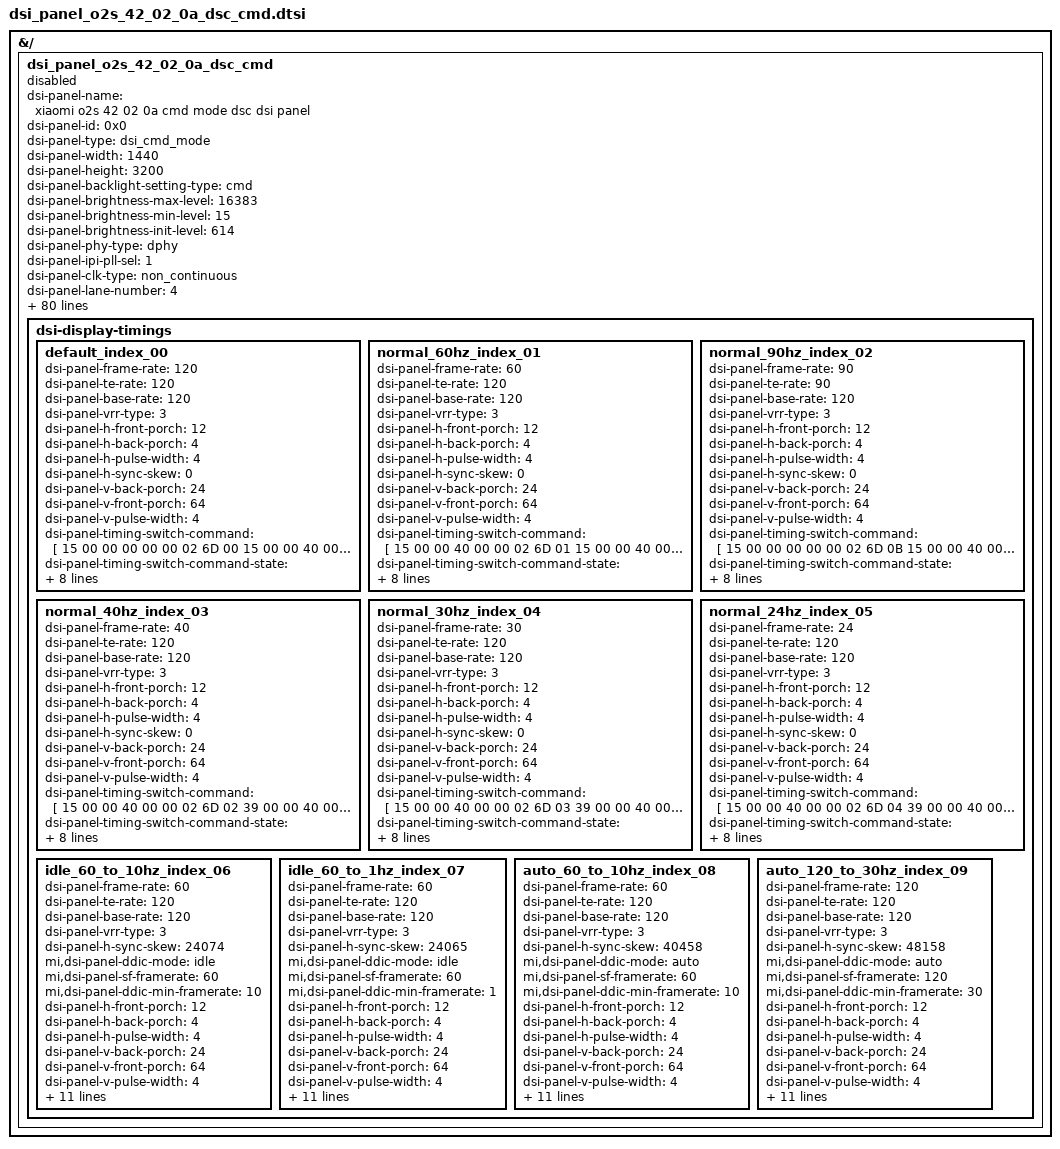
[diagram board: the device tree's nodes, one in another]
// SPDX-License-Identifier: GPL-2.0+
/*
 * DSI panel device tree for o2s testing
 *
 * (C) Copyright 2023 - 2024, X-Ring, Inc.
 */
&{/} {
	dsi_panel_o2s_42_02_0a_dsc_cmd: dsi_panel_o2s_42_02_0a_dsc_cmd {
		status = "disabled";
		dsi-panel-name = "xiaomi o2s 42 02 0a cmd mode dsc dsi panel";
		dsi-panel-id = <0x0>;
		dsi-panel-type = "dsi_cmd_mode";
		dsi-panel-width = <1440>;
		dsi-panel-height = <3200>;
		dsi-panel-backlight-setting-type = "cmd";
		dsi-panel-brightness-max-level = <16383>;
		dsi-panel-brightness-min-level = <15>;
		dsi-panel-brightness-init-level = <614>;
		dsi-panel-phy-type = "dphy";
		dsi-panel-ipi-pll-sel = <1>; // 0:phy pll 1:dpu pll
		dsi-panel-clk-type = "non_continuous";
		dsi-panel-lane-number = <4>;
		dsi-panel-lane-rate = <1360000000>; // 1.36GHz
		dsi-panel-pixel-clock = <26154000>; //26.154MHz
		dsi-panel-bpp = <30>;
		dsi-panel-virtual-channel = <0>;
		dsi-panel-bta-enable;
		dsi-panel-eotp-enable;
		dsi-panel-hdr-enabled;
		dsi-panel-peak-brightness = <12500000>;
		dsi-panel-blackness-level = <3230>;
		dsi-panel-physical-width-dimension = <701>;
		dsi-panel-physical-height-dimension = <1558>;
		dsi-panel-physical-type = "ltpo";
		dsi-panel-te-sel = /bits/ 8 <0x0>;
		dsi-panel-port-mask = /bits/ 8 <0x1>; // DSI-0: 0001
		dsi-panel-boot-up-profile = <1>; //profile-1
		dsi-panel-lowpower-ctrl = <0x3fd>;
		dsi-panel-frame-power-mask = <0x6>;
		dsi-panel-frame-power-max-refresh-rate = <30>;
		dsi-panel-hw-ulps-max-refresh-rate = <30>;
		dsi-panel-idle-policy = <0x0>;
		dsi-panel-dsc-compression-mode = "dsc";
		dsi-panel-dsc-version = <0x12>;
		dsi-panel-dsc-scr-version = <0>;
		dsi-panel-dsc-pic-height = <3200>;
		dsi-panel-dsc-pic-width = <1440>;
		dsi-panel-dsc-slice-height = <20>;
		dsi-panel-dsc-slice-width = <720>;
		dsi-panel-dsc-bpc = /bits/ 8 <10>;
		dsi-panel-dsc-bpp = /bits/ 8 <8>;
		dsi-panel-dsc-pps-table = [
			12 00 00 AB 30 80 0C 80 05 A0 00 14 02 D0 02 D0
			02 00 02 68 00 20 02 2E 00 0A 00 0C 05 0E 03 D1
			18 00 10 F0 07 10 20 00 06 0F 0F 33 0E 1C 2A 38
			46 54 62 69 70 77 79 7B 7D 7E 02 02 22 00 2A 40
			2A BE 3A FC 3A FA 3A F8 3B 38 3B 78 3B B6 4B B6
			4B F4 4B F4 6C 34 84 74 00 00 00 00 00 00 00 00
			00 00 00 00 00 00 00 00 00 00 00 00 00 00 00 00
			00 00 00 00 00 00 00 00 00 00 00 00 00 00 00 00
		];
		dsi-panel-vrr-enable;
		dsi-panel-reset-after-lp11;
		dsi-display-timings {
			default_index_00 {
				#include "dsi_panel_o2s_42_02_0a_dsc_cmd_common.dtsi"
				dsi-panel-frame-rate = <120>;
				dsi-panel-te-rate = <120>;
				dsi-panel-base-rate = <120>;
				dsi-panel-vrr-type = <3>;
				dsi-panel-h-front-porch = <12>;
				dsi-panel-h-back-porch = <4>;
				dsi-panel-h-pulse-width = <4>;
				dsi-panel-h-sync-skew = <0>;
				dsi-panel-v-back-porch = <24>;
				dsi-panel-v-front-porch = <64>;
				dsi-panel-v-pulse-width = <4>;
				dsi-panel-timing-switch-command = [
					//120hz
					15 00 00 00 00 00 02 6D 00
					//fix TE
					15 00 00 40 00 00 02 6F 14
					15 00 00 40 00 00 02 35 00
					15 00 00 40 00 00 02 6F 04
					15 00 00 00 00 00 02 35 00
				];
				dsi-panel-timing-switch-command-state = "dsi_hs_mode";
				dsi-panel-on-command = [
					#include "dsi_panel_o2s_42_02_0a_dsc_cmd_on_common.dtsi"
					//timing config
					15 00 00 40 00 00 02 2F 32
 					//120HZ
 					15 00 00 00 00 00 02 6D 00
 					//fix TE
 					15 00 00 40 00 00 02 6F 14
					15 00 00 40 00 00 02 35 00
					15 00 00 40 00 00 02 6F 04
					15 00 00 40 00 00 02 35 00
					15 00 00 00 00 00 02 5A 00
					//51 return in fps
					39 00 00 00 00 00 04 8C 00 00 11
					/* Sleep Out */
					05 00 00 00 78 00 01 11
					39 00 00 40 00 00 06 F0 55 AA 52 08 02
					15 00 00 00 00 00 02 CC 10
					39 00 00 40 00 00 06 F0 55 AA 52 08 09
					15 00 00 40 00 00 02 6F 03
					39 00 00 40 00 00 05 B2 20 24 28 2C
					15 00 00 40 00 00 02 B2 02
					15 00 00 40 00 00 02 DD 01
					15 00 00 40 00 00 02 6F 11
					39 00 00 40 00 00 20 B2 00 40 00 00 00 00 00 00 00 00 00 00 00 F0 FA
										FB FD 03 04 05 05 0D 0A 0A 02 02 02 02 00 00 00
					15 00 00 40 00 00 02 6F 11
					39 00 00 40 00 00 20 B2 01 40 00 00 00 00 00 00 00 00 00 0A 0A 07 06
										08 07 07 07 07 07 07 09 08 0A 05 06 05 00 00 00
					15 00 00 40 00 00 02 6F 11
					39 00 00 40 00 00 20 B2 00 41 00 00 00 00 00 00 00 F4 F4 F4 F4 FA FC
										00 02 0A 0C 0C 0A 0A 0A 0A 00 00 00 00 00 00 00
					15 00 00 40 00 00 02 6F 11
					39 00 00 40 00 00 20 B2 01 41 00 00 00 00 00 00 0D 0D 0D 0D 0F 0D 07
										08 07 07 07 07 06 05 05 05 05 04 03 00 00 00 00
					15 00 00 40 00 00 02 6F 11
					39 00 00 40 00 00 20 B2 00 42 00 00 00 00 00 01 01 01 DF FF FF 01 04
										08 0A 0A 12 0C 0A 0A 0A 0A 05 04 03 01 00 00 00
					15 00 00 40 00 00 02 6F 11
					39 00 00 40 00 00 20 B2 01 42 00 00 00 00 00 00 03 03 0A 0A 0A 0A 0B
										0B 0A 09 09 05 05 05 05 03 03 03 00 00 00 00 00
					15 00 00 40 00 00 02 6F 11
					39 00 00 40 00 00 20 B2 00 43 00 00 00 00 00 01 01 CA D7 03 FD 01 05
										0B 0E 06 06 09 0A 0A 08 04 00 00 00 00 00 00 00
					15 00 00 40 00 00 02 6F 11
					39 00 00 40 00 00 20 B2 01 43 00 00 00 00 00 00 03 F8 08 08 08 08 08
										08 0A 0A 04 04 05 05 05 FE 00 00 00 00 00 00 00
					15 00 00 40 00 00 02 6F 11
					39 00 00 40 00 00 20 B2 00 50 00 00 00 00 00 00 00 00 00 00 F3 F3 F3
										F7 F8 00 03 04 0C 0C 0A 0A 0A 06 06 06 00 00 00
					15 00 00 40 00 00 02 6F 11
					39 00 00 40 00 00 20 B2 01 50 00 00 00 00 00 00 00 00 00 0D 0D 0D 0D
										0A 0A 08 08 08 08 08 0A 0F 10 0F 07 08 00 00 00
					15 00 00 40 00 00 02 6F 11
					39 00 00 40 00 00 20 B2 00 51 00 00 00 00 00 00 00 00 00 00 E8 F0 F5
										FA 00 06 09 0A 09 05 09 02 02 00 00 00 00 00 00
					15 00 00 40 00 00 02 6F 11
					39 00 00 40 00 00 20 B2 01 51 00 00 00 00 00 00 00 00 00 00 0F 0F 09
										0B 0A 0A 07 08 08 08 06 04 02 02 02 01 00 00 00
					15 00 00 40 00 00 02 6F 11
					39 00 00 40 00 00 20 B2 00 52 00 00 00 00 00 00 00 00 00 F0 F0 F2 F8
										00 02 02 04 02 06 04 08 02 00 00 00 00 00 00 00
					15 00 00 40 00 00 02 6F 11
					39 00 00 40 00 00 20 B2 01 52 00 00 00 00 00 00 05 0B 0B 0A 0C 09 06
										06 09 0A 09 08 04 06 04 00 00 00 00 00 00 00 00
					15 00 00 40 00 00 02 6F 11
					39 00 00 40 00 00 20 B2 00 53 00 00 00 00 00 00 00 00 00 00 F0 F9 00
										02 02 01 02 02 06 04 08 02 00 00 00 00 00 00 00
					15 00 00 40 00 00 02 6F 11
					39 00 00 40 00 00 20 B2 01 53 00 00 00 00 00 00 05 0B 0B 0A 0C 07 0B
										0A 09 0A 09 08 04 06 04 00 00 00 00 00 00 00 00
					15 00 00 40 00 00 02 6F 11
					39 00 00 40 00 00 20 B2 00 60 00 00 00 00 00 00 00 00 00 00 DD 00 00
										00 00 00 00 00 00 03 08 04 08 06 06 06 00 00 00
					15 00 00 40 00 00 02 6F 11
					39 00 00 40 00 00 20 B2 01 60 00 00 00 00 00 00 00 00 00 00 11 0D 0D
										0A 0A 08 08 08 08 08 09 0A 12 0F 07 08 00 00 00
					15 00 00 40 00 00 02 6F 11
					39 00 00 40 00 00 20 B2 00 61 00 00 00 00 00 00 00 00 BD DD 00 E0 E6
										EC F5 FD 00 06 06 03 08 08 08 06 06 06 00 00 00
					15 00 00 40 00 00 02 6F 11
					39 00 00 40 00 00 20 B2 01 61 00 00 00 00 00 00 00 00 00 00 11 0D 0D
										0A 0A 08 08 08 08 08 0A 0F 10 0F 07 08 00 00 00
					15 00 00 40 00 00 02 6F 11
					39 00 00 40 00 00 20 B2 00 62 00 00 00 00 00 00 00 00 D7 F5 00 DC EC
										F4 03 06 08 08 06 16 0D 0A 0A 06 08 0A 00 00 00
					15 00 00 40 00 00 02 6F 11
					39 00 00 40 00 00 20 B2 01 62 00 00 00 00 00 00 00 00 0C 0C 0E 0D 0A
										09 0A 08 06 06 06 0F 0A 08 03 00 00 00 00 00 00
					15 00 00 40 00 00 02 6F 11
					39 00 00 40 00 00 20 B2 00 63 00 00 00 00 00 00 00 00 00 C7 EF EF FA
										00 0A 0A 0D 14 14 11 0F 0A 0A 06 08 0A 00 00 00
					15 00 00 40 00 00 02 6F 11
					39 00 00 40 00 00 20 B2 01 63 00 00 00 00 00 00 00 00 00 0D 10 0D 0A
										07 08 07 07 06 0A 07 06 05 00 00 00 00 00 00 00
					15 00 00 40 00 00 02 DD 00
					39 00 00 40 00 00 06 F0 55 AA 52 08 02
					15 00 00 00 00 00 02 CC 00
					//vgl lvd 9V
					39 00 00 40 00 00 06 F0 55 AA 52 08 01
					15 00 00 40 00 00 02 6F 03
					39 00 00 00 00 00 03 C7 E7 50
					//force cmd mode
					39 00 00 40 00 00 04 17 30 00 12
					39 00 00 40 00 00 05 FF AA 55 A5 81
					15 00 00 40 00 00 02 6F 0F
					39 00 00 00 00 00 02 FD 80
					//APL Dimming
					39 00 00 40 00 00 06 F0 55 AA 52 08 00
					15 00 00 40 00 00 02 6F 78
					39 00 00 40 00 00 18 B0 11 00 2A 00 C2 01 DA 03 7C 05 B1 08 80 0B EE 0F FF 05 55 05 56 05 55
					15 00 00 40 00 00 02 6F 6F
					39 00 00 40 00 00 07 B0 02 D0 05 A0 02 D0
					39 00 00 40 00 00 06 F0 55 AA 52 08 08
					//Lv0 1260nits
					39 00 00 40 00 00 17 C1 9D FF DD FF FF DD FF FF DD FF FF DD FF FF ED FF FF FF 7F FF 0D FF
					15 00 00 40 00 00 02 6F 1D
					39 00 00 40 00 00 07 C1 00 FF FF 4F 00 FF
					15 00 00 40 00 00 02 6F 23
					39 00 00 40 00 00 15 C1 0D FF DD FF FF DD FF FF DD FF FF DD FF FF ED FF FF BD 2D 00
					//Lv1 1800nits
					15 00 00 40 00 00 02 6F 37
					39 00 00 40 00 00 15 C1 0D FF DD FF FF DD FF FF DD FF FF DD FF FF ED FF FF FF 7F FF
					15 00 00 40 00 00 02 6F 4B
					39 00 00 40 00 00 15 C1 0D FF DD FF FF DD FF FF DD FF FF DD FF FF ED FF FF DF 7F 11
					39 00 00 40 00 00 2D BA 00 0F 00 1D 00 1D 00 31 00 31 00 53 00 53 01 9B 01 9B 01 9C
								01 9C 05 56 05 56 0F FF 0F FF 15 54 15 54 21 98 21 98 2F FD 2F FD 3F FF
					15 00 00 40 00 00 02 6F 07
					15 00 00 00 00 00 02 51 00
					/* Display On */
					05 00 00 00 00 00 01 29
					39 00 00 40 00 00 06 F0 55 AA 52 08 04
					15 00 00 40 00 00 02 6F 06
					39 00 00 00 00 00 04 CB 00 03 12
					39 00 00 40 00 00 06 F0 55 AA 52 08 08
					39 00 00 40 00 00 0F E1 00 00 00 00 00 00 00 00 00 00 00 00 00 00
					39 00 00 40 00 00 0F E2 00 00 00 00 02 05 08 0A 25 25 27 28 28 28
					39 00 00 00 00 00 0F E3 00 00 00 00 00 00 00 00 10 18 1A 1C 1E 20
					39 00 00 00 00 00 06 F0 55 AA 52 08 0F
				];
				dsi-panel-on-command-state = "dsi_lp_mode";
				mi,dsi-panel-nolp-command = [
					//exit AOD ESD detect 0A
					39 00 00 40 00 00 06 F0 55 AA 52 08 00
					15 00 00 40 00 00 02 6F 19
					39 00 00 40 00 00 05 BE 10 0A 00 9C
					05 00 00 40 00 00 01 38
					39 00 00 00 00 00 03 51 00 23
					//120hz
					15 00 00 00 00 00 02 6D 00
					//fix TE
					15 00 00 40 00 00 02 6F 14
					15 00 00 40 00 00 02 35 00
					15 00 00 40 00 00 02 6F 04
					15 00 00 40 00 00 02 35 00
					39 00 00 00 00 00 06 F0 55 AA 52 08 0F
				];
				mi,dsi-panel-nolp-command-update = <0x51 4 2>;
				mi,dsi-panel-nolp-command-state = "dsi_hs_mode";
			};
			normal_60hz_index_01 {
				#include "dsi_panel_o2s_42_02_0a_dsc_cmd_common.dtsi"
				dsi-panel-frame-rate = <60>;
				dsi-panel-te-rate = <120>;
				dsi-panel-base-rate = <120>;
				dsi-panel-vrr-type = <3>;
				dsi-panel-h-front-porch = <12>;
				dsi-panel-h-back-porch = <4>;
				dsi-panel-h-pulse-width = <4>;
				dsi-panel-h-sync-skew = <0>;
				dsi-panel-v-back-porch = <24>;
				dsi-panel-v-front-porch = <64>;
				dsi-panel-v-pulse-width = <4>;
				dsi-panel-timing-switch-command = [
					//60hz
					15 00 00 40 00 00 02 6D 01
					15 00 00 40 00 00 02 8C 00
					//fix TE
					15 00 00 40 00 00 02 6F 14
					15 00 00 40 00 00 02 35 00
					15 00 00 40 00 00 02 6F 04
					15 00 00 00 00 00 02 35 00
				];
				dsi-panel-timing-switch-command-state = "dsi_hs_mode";
				dsi-panel-on-command = [
					#include "dsi_panel_o2s_42_02_0a_dsc_cmd_on_common.dtsi"
					//timing config
					15 00 00 40 00 00 02 2F 32
 					//60hz
					15 00 00 40 00 00 02 6D 01
                                        15 00 00 00 00 00 02 8C 00
					//fix TE
					15 00 00 40 00 00 02 6F 14
					15 00 00 40 00 00 02 35 00
					15 00 00 40 00 00 02 6F 04
					15 00 00 40 00 00 02 35 00
					15 00 00 00 00 00 02 5A 00
					//51 return in fps
					39 00 00 00 00 00 04 8C 00 00 11
					/* Sleep Out */
					05 00 00 00 78 00 01 11
					39 00 00 40 00 00 06 F0 55 AA 52 08 02
					15 00 00 00 00 00 02 CC 10
					39 00 00 40 00 00 06 F0 55 AA 52 08 09
					15 00 00 40 00 00 02 6F 03
					39 00 00 40 00 00 05 B2 20 24 28 2C
					15 00 00 40 00 00 02 B2 02
					15 00 00 40 00 00 02 DD 01
					15 00 00 40 00 00 02 6F 11
					39 00 00 40 00 00 20 B2 00 40 00 00 00 00 00 00 00 00 00 00 00 F0 FA
										FB FD 03 04 05 05 0D 0A 0A 02 02 02 02 00 00 00
					15 00 00 40 00 00 02 6F 11
					39 00 00 40 00 00 20 B2 01 40 00 00 00 00 00 00 00 00 00 0A 0A 07 06
										08 07 07 07 07 07 07 09 08 0A 05 06 05 00 00 00
					15 00 00 40 00 00 02 6F 11
					39 00 00 40 00 00 20 B2 00 41 00 00 00 00 00 00 00 F4 F4 F4 F4 FA FC
										00 02 0A 0C 0C 0A 0A 0A 0A 00 00 00 00 00 00 00
					15 00 00 40 00 00 02 6F 11
					39 00 00 40 00 00 20 B2 01 41 00 00 00 00 00 00 0D 0D 0D 0D 0F 0D 07
										08 07 07 07 07 06 05 05 05 05 04 03 00 00 00 00
					15 00 00 40 00 00 02 6F 11
					39 00 00 40 00 00 20 B2 00 42 00 00 00 00 00 01 01 01 DF FF FF 01 04
										08 0A 0A 12 0C 0A 0A 0A 0A 05 04 03 01 00 00 00
					15 00 00 40 00 00 02 6F 11
					39 00 00 40 00 00 20 B2 01 42 00 00 00 00 00 00 03 03 0A 0A 0A 0A 0B
										0B 0A 09 09 05 05 05 05 03 03 03 00 00 00 00 00
					15 00 00 40 00 00 02 6F 11
					39 00 00 40 00 00 20 B2 00 43 00 00 00 00 00 01 01 CA D7 03 FD 01 05
										0B 0E 06 06 09 0A 0A 08 04 00 00 00 00 00 00 00
					15 00 00 40 00 00 02 6F 11
					39 00 00 40 00 00 20 B2 01 43 00 00 00 00 00 00 03 F8 08 08 08 08 08
										08 0A 0A 04 04 05 05 05 FE 00 00 00 00 00 00 00
					15 00 00 40 00 00 02 6F 11
					39 00 00 40 00 00 20 B2 00 50 00 00 00 00 00 00 00 00 00 00 F3 F3 F3
										F7 F8 00 03 04 0C 0C 0A 0A 0A 06 06 06 00 00 00
					15 00 00 40 00 00 02 6F 11
					39 00 00 40 00 00 20 B2 01 50 00 00 00 00 00 00 00 00 00 0D 0D 0D 0D
										0A 0A 08 08 08 08 08 0A 0F 10 0F 07 08 00 00 00
					15 00 00 40 00 00 02 6F 11
					39 00 00 40 00 00 20 B2 00 51 00 00 00 00 00 00 00 00 00 00 E8 F0 F5
										FA 00 06 09 0A 09 05 09 02 02 00 00 00 00 00 00
					15 00 00 40 00 00 02 6F 11
					39 00 00 40 00 00 20 B2 01 51 00 00 00 00 00 00 00 00 00 00 0F 0F 09
										0B 0A 0A 07 08 08 08 06 04 02 02 02 01 00 00 00
					15 00 00 40 00 00 02 6F 11
					39 00 00 40 00 00 20 B2 00 52 00 00 00 00 00 00 00 00 00 F0 F0 F2 F8
										00 02 02 04 02 06 04 08 02 00 00 00 00 00 00 00
					15 00 00 40 00 00 02 6F 11
					39 00 00 40 00 00 20 B2 01 52 00 00 00 00 00 00 05 0B 0B 0A 0C 09 06
										06 09 0A 09 08 04 06 04 00 00 00 00 00 00 00 00
					15 00 00 40 00 00 02 6F 11
					39 00 00 40 00 00 20 B2 00 53 00 00 00 00 00 00 00 00 00 00 F0 F9 00
										02 02 01 02 02 06 04 08 02 00 00 00 00 00 00 00
					15 00 00 40 00 00 02 6F 11
					39 00 00 40 00 00 20 B2 01 53 00 00 00 00 00 00 05 0B 0B 0A 0C 07 0B
										0A 09 0A 09 08 04 06 04 00 00 00 00 00 00 00 00
					15 00 00 40 00 00 02 6F 11
					39 00 00 40 00 00 20 B2 00 60 00 00 00 00 00 00 00 00 00 00 DD 00 00
										00 00 00 00 00 00 03 08 04 08 06 06 06 00 00 00
					15 00 00 40 00 00 02 6F 11
					39 00 00 40 00 00 20 B2 01 60 00 00 00 00 00 00 00 00 00 00 11 0D 0D
										0A 0A 08 08 08 08 08 09 0A 12 0F 07 08 00 00 00
					15 00 00 40 00 00 02 6F 11
					39 00 00 40 00 00 20 B2 00 61 00 00 00 00 00 00 00 00 BD DD 00 E0 E6
										EC F5 FD 00 06 06 03 08 08 08 06 06 06 00 00 00
					15 00 00 40 00 00 02 6F 11
					39 00 00 40 00 00 20 B2 01 61 00 00 00 00 00 00 00 00 00 00 11 0D 0D
										0A 0A 08 08 08 08 08 0A 0F 10 0F 07 08 00 00 00
					15 00 00 40 00 00 02 6F 11
					39 00 00 40 00 00 20 B2 00 62 00 00 00 00 00 00 00 00 D7 F5 00 DC EC
										F4 03 06 08 08 06 16 0D 0A 0A 06 08 0A 00 00 00
					15 00 00 40 00 00 02 6F 11
					39 00 00 40 00 00 20 B2 01 62 00 00 00 00 00 00 00 00 0C 0C 0E 0D 0A
										09 0A 08 06 06 06 0F 0A 08 03 00 00 00 00 00 00
					15 00 00 40 00 00 02 6F 11
					39 00 00 40 00 00 20 B2 00 63 00 00 00 00 00 00 00 00 00 C7 EF EF FA
										00 0A 0A 0D 14 14 11 0F 0A 0A 06 08 0A 00 00 00
					15 00 00 40 00 00 02 6F 11
					39 00 00 40 00 00 20 B2 01 63 00 00 00 00 00 00 00 00 00 0D 10 0D 0A
										07 08 07 07 06 0A 07 06 05 00 00 00 00 00 00 00
					15 00 00 40 00 00 02 DD 00
					39 00 00 40 00 00 06 F0 55 AA 52 08 02
					15 00 00 00 00 00 02 CC 00
					//vgl lvd 9V
					39 00 00 40 00 00 06 F0 55 AA 52 08 01
					15 00 00 40 00 00 02 6F 03
					39 00 00 00 00 00 03 C7 E7 50
					//force cmd mode
					39 00 00 40 00 00 04 17 30 00 12
					39 00 00 40 00 00 05 FF AA 55 A5 81
					15 00 00 40 00 00 02 6F 0F
					39 00 00 00 00 00 02 FD 80
					//APL Dimming
					39 00 00 40 00 00 06 F0 55 AA 52 08 00
					15 00 00 40 00 00 02 6F 78
					39 00 00 40 00 00 18 B0 11 00 2A 00 C2 01 DA 03 7C 05 B1 08 80 0B EE 0F FF 05 55 05 56 05 55
					15 00 00 40 00 00 02 6F 6F
					39 00 00 40 00 00 07 B0 02 D0 05 A0 02 D0
					39 00 00 40 00 00 06 F0 55 AA 52 08 08
					//Lv0 1260nits
					39 00 00 40 00 00 17 C1 9D FF DD FF FF DD FF FF DD FF FF DD FF FF ED FF FF FF 7F FF 0D FF
					15 00 00 40 00 00 02 6F 1D
					39 00 00 40 00 00 07 C1 00 FF FF 4F 00 FF
					15 00 00 40 00 00 02 6F 23
					39 00 00 40 00 00 15 C1 0D FF DD FF FF DD FF FF DD FF FF DD FF FF ED FF FF BD 2D 00
					//Lv1 1800nits
					15 00 00 40 00 00 02 6F 37
					39 00 00 40 00 00 15 C1 0D FF DD FF FF DD FF FF DD FF FF DD FF FF ED FF FF FF 7F FF
					15 00 00 40 00 00 02 6F 4B
					39 00 00 40 00 00 15 C1 0D FF DD FF FF DD FF FF DD FF FF DD FF FF ED FF FF DF 7F 11
					39 00 00 40 00 00 2D BA 00 0F 00 1D 00 1D 00 31 00 31 00 53 00 53 01 9B 01 9B 01 9C
								01 9C 05 56 05 56 0F FF 0F FF 15 54 15 54 21 98 21 98 2F FD 2F FD 3F FF
					15 00 00 40 00 00 02 6F 07
					15 00 00 00 00 00 02 51 00
					/* Display On */
					05 00 00 00 00 00 01 29
					39 00 00 40 00 00 06 F0 55 AA 52 08 04
					15 00 00 40 00 00 02 6F 06
					39 00 00 00 00 00 04 CB 00 03 12
					39 00 00 40 00 00 06 F0 55 AA 52 08 08
					39 00 00 40 00 00 0F E1 00 00 00 00 00 00 00 00 00 00 00 00 00 00
					39 00 00 40 00 00 0F E2 00 00 00 00 02 05 08 0A 25 25 27 28 28 28
					39 00 00 00 00 00 0F E3 00 00 00 00 00 00 00 00 10 18 1A 1C 1E 20
					39 00 00 00 00 00 06 F0 55 AA 52 08 0F
				];
				dsi-panel-on-command-state = "dsi_lp_mode";
				mi,dsi-panel-nolp-command = [
					//exit AOD ESD detect 0A
					39 00 00 40 00 00 06 F0 55 AA 52 08 00
					15 00 00 40 00 00 02 6F 19
					39 00 00 40 00 00 05 BE 10 0A 00 9C
					05 00 00 40 00 00 01 38
					39 00 00 00 00 00 03 51 00 23
					//60hz
					15 00 00 40 00 00 02 6D 01
					15 00 00 40 00 00 02 8C 00
					//fix TE
					15 00 00 40 00 00 02 6F 14
					15 00 00 40 00 00 02 35 00
					15 00 00 40 00 00 02 6F 04
					15 00 00 40 00 00 02 35 00
					39 00 00 00 00 00 06 F0 55 AA 52 08 0F
				];
				mi,dsi-panel-nolp-command-update = <0x51 4 2>;
				mi,dsi-panel-nolp-command-state = "dsi_hs_mode";
			};
			normal_90hz_index_02 {
				#include "dsi_panel_o2s_42_02_0a_dsc_cmd_common.dtsi"
				dsi-panel-frame-rate = <90>;
				dsi-panel-te-rate = <90>;
				dsi-panel-base-rate = <120>;
				dsi-panel-vrr-type = <3>;
				dsi-panel-h-front-porch = <12>;
				dsi-panel-h-back-porch = <4>;
				dsi-panel-h-pulse-width = <4>;
				dsi-panel-h-sync-skew = <0>;
				dsi-panel-v-back-porch = <24>;
				dsi-panel-v-front-porch = <64>;
				dsi-panel-v-pulse-width = <4>;
				dsi-panel-timing-switch-command = [
					//90hz
					15 00 00 00 00 00 02 6D 0B
					//fix TE
					15 00 00 40 00 00 02 6F 14
					15 00 00 40 00 00 02 35 00
					15 00 00 40 00 00 02 6F 04
					15 00 00 00 00 00 02 35 00
				];
				dsi-panel-timing-switch-command-state = "dsi_hs_mode";
				dsi-panel-on-command = [
					#include "dsi_panel_o2s_42_02_0a_dsc_cmd_on_common.dtsi"
					//timing config
					15 00 00 40 00 00 02 2F 32
 					//90HZ
 					15 00 00 40 00 00 02 6D 0B
 					//fix TE
 					15 00 00 40 00 00 02 6F 14
					15 00 00 40 00 00 02 35 00
					15 00 00 40 00 00 02 6F 04
					15 00 00 40 00 00 02 35 00
					15 00 00 00 00 00 02 5A 00
					//51 return in fps
					39 00 00 00 00 00 04 8C 00 00 11
					/* Sleep Out */
					05 00 00 00 78 00 01 11
					39 00 00 40 00 00 06 F0 55 AA 52 08 02
					15 00 00 00 00 00 02 CC 10
					39 00 00 40 00 00 06 F0 55 AA 52 08 09
					15 00 00 40 00 00 02 6F 03
					39 00 00 40 00 00 05 B2 20 24 28 2C
					15 00 00 40 00 00 02 B2 02
					15 00 00 40 00 00 02 DD 01
					15 00 00 40 00 00 02 6F 11
					39 00 00 40 00 00 20 B2 00 40 00 00 00 00 00 00 00 00 00 00 00 F0 FA
										FB FD 03 04 05 05 0D 0A 0A 02 02 02 02 00 00 00
					15 00 00 40 00 00 02 6F 11
					39 00 00 40 00 00 20 B2 01 40 00 00 00 00 00 00 00 00 00 0A 0A 07 06
										08 07 07 07 07 07 07 09 08 0A 05 06 05 00 00 00
					15 00 00 40 00 00 02 6F 11
					39 00 00 40 00 00 20 B2 00 41 00 00 00 00 00 00 00 F4 F4 F4 F4 FA FC
										00 02 0A 0C 0C 0A 0A 0A 0A 00 00 00 00 00 00 00
					15 00 00 40 00 00 02 6F 11
					39 00 00 40 00 00 20 B2 01 41 00 00 00 00 00 00 0D 0D 0D 0D 0F 0D 07
										08 07 07 07 07 06 05 05 05 05 04 03 00 00 00 00
					15 00 00 40 00 00 02 6F 11
					39 00 00 40 00 00 20 B2 00 42 00 00 00 00 00 01 01 01 DF FF FF 01 04
										08 0A 0A 12 0C 0A 0A 0A 0A 05 04 03 01 00 00 00
					15 00 00 40 00 00 02 6F 11
					39 00 00 40 00 00 20 B2 01 42 00 00 00 00 00 00 03 03 0A 0A 0A 0A 0B
										0B 0A 09 09 05 05 05 05 03 03 03 00 00 00 00 00
					15 00 00 40 00 00 02 6F 11
					39 00 00 40 00 00 20 B2 00 43 00 00 00 00 00 01 01 CA D7 03 FD 01 05
										0B 0E 06 06 09 0A 0A 08 04 00 00 00 00 00 00 00
					15 00 00 40 00 00 02 6F 11
					39 00 00 40 00 00 20 B2 01 43 00 00 00 00 00 00 03 F8 08 08 08 08 08
										08 0A 0A 04 04 05 05 05 FE 00 00 00 00 00 00 00
					15 00 00 40 00 00 02 6F 11
					39 00 00 40 00 00 20 B2 00 50 00 00 00 00 00 00 00 00 00 00 F3 F3 F3
										F7 F8 00 03 04 0C 0C 0A 0A 0A 06 06 06 00 00 00
					15 00 00 40 00 00 02 6F 11
					39 00 00 40 00 00 20 B2 01 50 00 00 00 00 00 00 00 00 00 0D 0D 0D 0D
										0A 0A 08 08 08 08 08 0A 0F 10 0F 07 08 00 00 00
					15 00 00 40 00 00 02 6F 11
					39 00 00 40 00 00 20 B2 00 51 00 00 00 00 00 00 00 00 00 00 E8 F0 F5
										FA 00 06 09 0A 09 05 09 02 02 00 00 00 00 00 00
					15 00 00 40 00 00 02 6F 11
					39 00 00 40 00 00 20 B2 01 51 00 00 00 00 00 00 00 00 00 00 0F 0F 09
										0B 0A 0A 07 08 08 08 06 04 02 02 02 01 00 00 00
					15 00 00 40 00 00 02 6F 11
					39 00 00 40 00 00 20 B2 00 52 00 00 00 00 00 00 00 00 00 F0 F0 F2 F8
										00 02 02 04 02 06 04 08 02 00 00 00 00 00 00 00
					15 00 00 40 00 00 02 6F 11
					39 00 00 40 00 00 20 B2 01 52 00 00 00 00 00 00 05 0B 0B 0A 0C 09 06
										06 09 0A 09 08 04 06 04 00 00 00 00 00 00 00 00
					15 00 00 40 00 00 02 6F 11
					39 00 00 40 00 00 20 B2 00 53 00 00 00 00 00 00 00 00 00 00 F0 F9 00
										02 02 01 02 02 06 04 08 02 00 00 00 00 00 00 00
					15 00 00 40 00 00 02 6F 11
					39 00 00 40 00 00 20 B2 01 53 00 00 00 00 00 00 05 0B 0B 0A 0C 07 0B
										0A 09 0A 09 08 04 06 04 00 00 00 00 00 00 00 00
					15 00 00 40 00 00 02 6F 11
					39 00 00 40 00 00 20 B2 00 60 00 00 00 00 00 00 00 00 00 00 DD 00 00
										00 00 00 00 00 00 03 08 04 08 06 06 06 00 00 00
					15 00 00 40 00 00 02 6F 11
					39 00 00 40 00 00 20 B2 01 60 00 00 00 00 00 00 00 00 00 00 11 0D 0D
										0A 0A 08 08 08 08 08 09 0A 12 0F 07 08 00 00 00
					15 00 00 40 00 00 02 6F 11
					39 00 00 40 00 00 20 B2 00 61 00 00 00 00 00 00 00 00 BD DD 00 E0 E6
										EC F5 FD 00 06 06 03 08 08 08 06 06 06 00 00 00
					15 00 00 40 00 00 02 6F 11
					39 00 00 40 00 00 20 B2 01 61 00 00 00 00 00 00 00 00 00 00 11 0D 0D
										0A 0A 08 08 08 08 08 0A 0F 10 0F 07 08 00 00 00
					15 00 00 40 00 00 02 6F 11
					39 00 00 40 00 00 20 B2 00 62 00 00 00 00 00 00 00 00 D7 F5 00 DC EC
										F4 03 06 08 08 06 16 0D 0A 0A 06 08 0A 00 00 00
					15 00 00 40 00 00 02 6F 11
					39 00 00 40 00 00 20 B2 01 62 00 00 00 00 00 00 00 00 0C 0C 0E 0D 0A
										09 0A 08 06 06 06 0F 0A 08 03 00 00 00 00 00 00
					15 00 00 40 00 00 02 6F 11
					39 00 00 40 00 00 20 B2 00 63 00 00 00 00 00 00 00 00 00 C7 EF EF FA
										00 0A 0A 0D 14 14 11 0F 0A 0A 06 08 0A 00 00 00
					15 00 00 40 00 00 02 6F 11
					39 00 00 40 00 00 20 B2 01 63 00 00 00 00 00 00 00 00 00 0D 10 0D 0A
										07 08 07 07 06 0A 07 06 05 00 00 00 00 00 00 00
					15 00 00 40 00 00 02 DD 00
					39 00 00 40 00 00 06 F0 55 AA 52 08 02
					15 00 00 00 00 00 02 CC 00
					//vgl lvd 9V
					39 00 00 40 00 00 06 F0 55 AA 52 08 01
					15 00 00 40 00 00 02 6F 03
					39 00 00 00 00 00 03 C7 E7 50
					//force cmd mode
					39 00 00 40 00 00 04 17 30 00 12
					39 00 00 40 00 00 05 FF AA 55 A5 81
					15 00 00 40 00 00 02 6F 0F
					39 00 00 00 00 00 02 FD 80
					//APL Dimming
					39 00 00 40 00 00 06 F0 55 AA 52 08 00
					15 00 00 40 00 00 02 6F 78
					39 00 00 40 00 00 18 B0 11 00 2A 00 C2 01 DA 03 7C 05 B1 08 80 0B EE 0F FF 05 55 05 56 05 55
					15 00 00 40 00 00 02 6F 6F
					39 00 00 40 00 00 07 B0 02 D0 05 A0 02 D0
					39 00 00 40 00 00 06 F0 55 AA 52 08 08
					//Lv0 1260nits
					39 00 00 40 00 00 17 C1 9D FF DD FF FF DD FF FF DD FF FF DD FF FF ED FF FF FF 7F FF 0D FF
					15 00 00 40 00 00 02 6F 1D
					39 00 00 40 00 00 07 C1 00 FF FF 4F 00 FF
					15 00 00 40 00 00 02 6F 23
					39 00 00 40 00 00 15 C1 0D FF DD FF FF DD FF FF DD FF FF DD FF FF ED FF FF BD 2D 00
					//Lv1 1800nits
					15 00 00 40 00 00 02 6F 37
					39 00 00 40 00 00 15 C1 0D FF DD FF FF DD FF FF DD FF FF DD FF FF ED FF FF FF 7F FF
					15 00 00 40 00 00 02 6F 4B
					39 00 00 40 00 00 15 C1 0D FF DD FF FF DD FF FF DD FF FF DD FF FF ED FF FF DF 7F 11
					39 00 00 40 00 00 2D BA 00 0F 00 1D 00 1D 00 31 00 31 00 53 00 53 01 9B 01 9B 01 9C
								01 9C 05 56 05 56 0F FF 0F FF 15 54 15 54 21 98 21 98 2F FD 2F FD 3F FF
					15 00 00 40 00 00 02 6F 07
					15 00 00 00 00 00 02 51 00
					/* Display On */
					05 00 00 00 00 00 01 29
					39 00 00 40 00 00 06 F0 55 AA 52 08 04
					15 00 00 40 00 00 02 6F 06
					39 00 00 00 00 00 04 CB 00 03 12
					39 00 00 40 00 00 06 F0 55 AA 52 08 08
					39 00 00 40 00 00 0F E1 00 00 00 00 00 00 00 00 00 00 00 00 00 00
					39 00 00 40 00 00 0F E2 00 00 00 00 02 05 08 0A 25 25 27 28 28 28
					39 00 00 00 00 00 0F E3 00 00 00 00 00 00 00 00 10 18 1A 1C 1E 20
					39 00 00 00 00 00 06 F0 55 AA 52 08 0F
				];
				dsi-panel-on-command-state = "dsi_lp_mode";
				mi,dsi-panel-nolp-command = [
					//exit AOD ESD detect 0A
					39 00 00 40 00 00 06 F0 55 AA 52 08 00
					15 00 00 40 00 00 02 6F 19
					39 00 00 40 00 00 05 BE 10 0A 00 9C
					05 00 00 40 00 00 01 38
					39 00 00 00 00 00 03 51 00 23
					//90hz
					15 00 00 00 00 00 02 6D 0B
					//fix TE
					15 00 00 40 00 00 02 6F 14
					15 00 00 40 00 00 02 35 00
					15 00 00 40 00 00 02 6F 04
					15 00 00 40 00 00 02 35 00
					39 00 00 00 00 00 06 F0 55 AA 52 08 0F
				];
				mi,dsi-panel-nolp-command-update = <0x51 4 2>;
				mi,dsi-panel-nolp-command-state = "dsi_hs_mode";
			};
		normal_40hz_index_03 {
				#include "dsi_panel_o2s_42_02_0a_dsc_cmd_common.dtsi"
				dsi-panel-frame-rate = <40>;
				dsi-panel-te-rate = <120>;
				dsi-panel-base-rate = <120>;
				dsi-panel-vrr-type = <3>;
				dsi-panel-h-front-porch = <12>;
				dsi-panel-h-back-porch = <4>;
				dsi-panel-h-pulse-width = <4>;
				dsi-panel-h-sync-skew = <0>;
				dsi-panel-v-back-porch = <24>;
				dsi-panel-v-front-porch = <64>;
				dsi-panel-v-pulse-width = <4>;
				dsi-panel-timing-switch-command = [
					//40hz
					15 00 00 40 00 00 02 6D 02
					39 00 00 40 00 00 06 F0 55 AA 52 08 00
					15 00 00 40 00 00 02 6F DE
					15 00 00 40 00 00 02 BA 04
					15 00 00 40 00 00 02 8C 00
					39 00 00 40 00 00 08 A2 03 01 00 8C 00 00 02
					05 00 00 40 00 00 01 A9
					//fix TE
					15 00 00 40 00 00 02 6F 14
					15 00 00 40 00 00 02 35 00
					15 00 00 40 00 00 02 6F 04
					15 00 00 00 00 00 02 35 00
				];
				dsi-panel-timing-switch-command-state = "dsi_hs_mode";
				dsi-panel-on-command = [
					#include "dsi_panel_o2s_42_02_0a_dsc_cmd_on_common.dtsi"
					//timing config
					15 00 00 40 00 00 02 2F 32
 					//40HZ
					15 00 00 40 00 00 02 6D 02
					39 00 00 40 00 00 06 F0 55 AA 52 08 00
					15 00 00 40 00 00 02 6F DE
					15 00 00 40 00 00 02 BA 04
					15 00 00 40 00 00 02 8C 00
					39 00 00 40 00 00 08 A2 03 01 00 8C 00 00 02
					05 00 00 40 00 00 01 A9
					//fix TE
					15 00 00 40 00 00 02 6F 14
					15 00 00 40 00 00 02 35 00
					15 00 00 40 00 00 02 6F 04
					15 00 00 40 00 00 02 35 00
					15 00 00 00 00 00 02 5A 00
					//51 return in fps
					39 00 00 00 00 00 04 8C 00 00 11
					/* Sleep Out */
					05 00 00 00 78 00 01 11
					39 00 00 40 00 00 06 F0 55 AA 52 08 02
					15 00 00 00 00 00 02 CC 10
					39 00 00 40 00 00 06 F0 55 AA 52 08 09
					15 00 00 40 00 00 02 6F 03
					39 00 00 40 00 00 05 B2 20 24 28 2C
					15 00 00 40 00 00 02 B2 02
					15 00 00 40 00 00 02 DD 01
					15 00 00 40 00 00 02 6F 11
					39 00 00 40 00 00 20 B2 00 40 00 00 00 00 00 00 00 00 00 00 00 F0 FA
										FB FD 03 04 05 05 0D 0A 0A 02 02 02 02 00 00 00
					15 00 00 40 00 00 02 6F 11
					39 00 00 40 00 00 20 B2 01 40 00 00 00 00 00 00 00 00 00 0A 0A 07 06
										08 07 07 07 07 07 07 09 08 0A 05 06 05 00 00 00
					15 00 00 40 00 00 02 6F 11
					39 00 00 40 00 00 20 B2 00 41 00 00 00 00 00 00 00 F4 F4 F4 F4 FA FC
										00 02 0A 0C 0C 0A 0A 0A 0A 00 00 00 00 00 00 00
					15 00 00 40 00 00 02 6F 11
					39 00 00 40 00 00 20 B2 01 41 00 00 00 00 00 00 0D 0D 0D 0D 0F 0D 07
										08 07 07 07 07 06 05 05 05 05 04 03 00 00 00 00
					15 00 00 40 00 00 02 6F 11
					39 00 00 40 00 00 20 B2 00 42 00 00 00 00 00 01 01 01 DF FF FF 01 04
										08 0A 0A 12 0C 0A 0A 0A 0A 05 04 03 01 00 00 00
					15 00 00 40 00 00 02 6F 11
					39 00 00 40 00 00 20 B2 01 42 00 00 00 00 00 00 03 03 0A 0A 0A 0A 0B
										0B 0A 09 09 05 05 05 05 03 03 03 00 00 00 00 00
					15 00 00 40 00 00 02 6F 11
					39 00 00 40 00 00 20 B2 00 43 00 00 00 00 00 01 01 CA D7 03 FD 01 05
										0B 0E 06 06 09 0A 0A 08 04 00 00 00 00 00 00 00
					15 00 00 40 00 00 02 6F 11
					39 00 00 40 00 00 20 B2 01 43 00 00 00 00 00 00 03 F8 08 08 08 08 08
										08 0A 0A 04 04 05 05 05 FE 00 00 00 00 00 00 00
					15 00 00 40 00 00 02 6F 11
					39 00 00 40 00 00 20 B2 00 50 00 00 00 00 00 00 00 00 00 00 F3 F3 F3
										F7 F8 00 03 04 0C 0C 0A 0A 0A 06 06 06 00 00 00
					15 00 00 40 00 00 02 6F 11
					39 00 00 40 00 00 20 B2 01 50 00 00 00 00 00 00 00 00 00 0D 0D 0D 0D
										0A 0A 08 08 08 08 08 0A 0F 10 0F 07 08 00 00 00
					15 00 00 40 00 00 02 6F 11
					39 00 00 40 00 00 20 B2 00 51 00 00 00 00 00 00 00 00 00 00 E8 F0 F5
										FA 00 06 09 0A 09 05 09 02 02 00 00 00 00 00 00
					15 00 00 40 00 00 02 6F 11
					39 00 00 40 00 00 20 B2 01 51 00 00 00 00 00 00 00 00 00 00 0F 0F 09
										0B 0A 0A 07 08 08 08 06 04 02 02 02 01 00 00 00
					15 00 00 40 00 00 02 6F 11
					39 00 00 40 00 00 20 B2 00 52 00 00 00 00 00 00 00 00 00 F0 F0 F2 F8
										00 02 02 04 02 06 04 08 02 00 00 00 00 00 00 00
					15 00 00 40 00 00 02 6F 11
					39 00 00 40 00 00 20 B2 01 52 00 00 00 00 00 00 05 0B 0B 0A 0C 09 06
										06 09 0A 09 08 04 06 04 00 00 00 00 00 00 00 00
					15 00 00 40 00 00 02 6F 11
					39 00 00 40 00 00 20 B2 00 53 00 00 00 00 00 00 00 00 00 00 F0 F9 00
										02 02 01 02 02 06 04 08 02 00 00 00 00 00 00 00
					15 00 00 40 00 00 02 6F 11
					39 00 00 40 00 00 20 B2 01 53 00 00 00 00 00 00 05 0B 0B 0A 0C 07 0B
										0A 09 0A 09 08 04 06 04 00 00 00 00 00 00 00 00
					15 00 00 40 00 00 02 6F 11
					39 00 00 40 00 00 20 B2 00 60 00 00 00 00 00 00 00 00 00 00 DD 00 00
										00 00 00 00 00 00 03 08 04 08 06 06 06 00 00 00
					15 00 00 40 00 00 02 6F 11
					39 00 00 40 00 00 20 B2 01 60 00 00 00 00 00 00 00 00 00 00 11 0D 0D
										0A 0A 08 08 08 08 08 09 0A 12 0F 07 08 00 00 00
					15 00 00 40 00 00 02 6F 11
					39 00 00 40 00 00 20 B2 00 61 00 00 00 00 00 00 00 00 BD DD 00 E0 E6
										EC F5 FD 00 06 06 03 08 08 08 06 06 06 00 00 00
					15 00 00 40 00 00 02 6F 11
					39 00 00 40 00 00 20 B2 01 61 00 00 00 00 00 00 00 00 00 00 11 0D 0D
										0A 0A 08 08 08 08 08 0A 0F 10 0F 07 08 00 00 00
					15 00 00 40 00 00 02 6F 11
					39 00 00 40 00 00 20 B2 00 62 00 00 00 00 00 00 00 00 D7 F5 00 DC EC
										F4 03 06 08 08 06 16 0D 0A 0A 06 08 0A 00 00 00
					15 00 00 40 00 00 02 6F 11
					39 00 00 40 00 00 20 B2 01 62 00 00 00 00 00 00 00 00 0C 0C 0E 0D 0A
										09 0A 08 06 06 06 0F 0A 08 03 00 00 00 00 00 00
					15 00 00 40 00 00 02 6F 11
					39 00 00 40 00 00 20 B2 00 63 00 00 00 00 00 00 00 00 00 C7 EF EF FA
										00 0A 0A 0D 14 14 11 0F 0A 0A 06 08 0A 00 00 00
					15 00 00 40 00 00 02 6F 11
					39 00 00 40 00 00 20 B2 01 63 00 00 00 00 00 00 00 00 00 0D 10 0D 0A
										07 08 07 07 06 0A 07 06 05 00 00 00 00 00 00 00
					15 00 00 40 00 00 02 DD 00
					39 00 00 40 00 00 06 F0 55 AA 52 08 02
					15 00 00 00 00 00 02 CC 00
					//vgl lvd 9V
					39 00 00 40 00 00 06 F0 55 AA 52 08 01
					15 00 00 40 00 00 02 6F 03
					39 00 00 00 00 00 03 C7 E7 50
					//force cmd mode
					39 00 00 40 00 00 04 17 30 00 12
					39 00 00 40 00 00 05 FF AA 55 A5 81
					15 00 00 40 00 00 02 6F 0F
					39 00 00 00 00 00 02 FD 80
					//APL Dimming
					39 00 00 40 00 00 06 F0 55 AA 52 08 00
					15 00 00 40 00 00 02 6F 78
					39 00 00 40 00 00 18 B0 11 00 2A 00 C2 01 DA 03 7C 05 B1 08 80 0B EE 0F FF 05 55 05 56 05 55
					15 00 00 40 00 00 02 6F 6F
					39 00 00 40 00 00 07 B0 02 D0 05 A0 02 D0
					39 00 00 40 00 00 06 F0 55 AA 52 08 08
					//Lv0 1260nits
					39 00 00 40 00 00 17 C1 9D FF DD FF FF DD FF FF DD FF FF DD FF FF ED FF FF FF 7F FF 0D FF
					15 00 00 40 00 00 02 6F 1D
					39 00 00 40 00 00 07 C1 00 FF FF 4F 00 FF
					15 00 00 40 00 00 02 6F 23
					39 00 00 40 00 00 15 C1 0D FF DD FF FF DD FF FF DD FF FF DD FF FF ED FF FF BD 2D 00
					//Lv1 1800nits
					15 00 00 40 00 00 02 6F 37
					39 00 00 40 00 00 15 C1 0D FF DD FF FF DD FF FF DD FF FF DD FF FF ED FF FF FF 7F FF
					15 00 00 40 00 00 02 6F 4B
					39 00 00 40 00 00 15 C1 0D FF DD FF FF DD FF FF DD FF FF DD FF FF ED FF FF DF 7F 11
					39 00 00 40 00 00 2D BA 00 0F 00 1D 00 1D 00 31 00 31 00 53 00 53 01 9B 01 9B 01 9C
								01 9C 05 56 05 56 0F FF 0F FF 15 54 15 54 21 98 21 98 2F FD 2F FD 3F FF
					15 00 00 40 00 00 02 6F 07
					15 00 00 00 00 00 02 51 00
					/* Display On */
					05 00 00 00 00 00 01 29
					39 00 00 40 00 00 06 F0 55 AA 52 08 04
					15 00 00 40 00 00 02 6F 06
					39 00 00 00 00 00 04 CB 00 03 12
					39 00 00 40 00 00 06 F0 55 AA 52 08 08
					39 00 00 40 00 00 0F E1 00 00 00 00 00 00 00 00 00 00 00 00 00 00
					39 00 00 40 00 00 0F E2 00 00 00 00 02 05 08 0A 25 25 27 28 28 28
					39 00 00 00 00 00 0F E3 00 00 00 00 00 00 00 00 10 18 1A 1C 1E 20
					39 00 00 00 00 00 06 F0 55 AA 52 08 0F
				];
				dsi-panel-on-command-state = "dsi_lp_mode";
				mi,dsi-panel-nolp-command = [
					//exit AOD ESD detect 0A
					39 00 00 40 00 00 06 F0 55 AA 52 08 00
					15 00 00 40 00 00 02 6F 19
					39 00 00 40 00 00 05 BE 10 0A 00 9C
					05 00 00 40 00 00 01 38
					39 00 00 00 00 00 03 51 00 23
					//40hz
					15 00 00 40 00 00 02 6D 02
					39 00 00 40 00 00 06 F0 55 AA 52 08 00
					15 00 00 40 00 00 02 6F DE
					15 00 00 40 00 00 02 BA 04
					15 00 00 40 00 00 02 8C 00
					39 00 00 40 00 00 08 A2 03 01 00 8C 00 00 02
					05 00 00 40 00 00 01 A9
					//fix TE
					15 00 00 40 00 00 02 6F 14
					15 00 00 40 00 00 02 35 00
					15 00 00 40 00 00 02 6F 04
					15 00 00 40 00 00 02 35 00
					39 00 00 00 00 00 06 F0 55 AA 52 08 0F
				];
				mi,dsi-panel-nolp-command-update = <0x51 4 2>;
				mi,dsi-panel-nolp-command-state = "dsi_hs_mode";
			};
		normal_30hz_index_04 {
				#include "dsi_panel_o2s_42_02_0a_dsc_cmd_common.dtsi"
				dsi-panel-frame-rate = <30>;
				dsi-panel-te-rate = <120>;
				dsi-panel-base-rate = <120>;
				dsi-panel-vrr-type = <3>;
				dsi-panel-h-front-porch = <12>;
				dsi-panel-h-back-porch = <4>;
				dsi-panel-h-pulse-width = <4>;
				dsi-panel-h-sync-skew = <0>;
				dsi-panel-v-back-porch = <24>;
				dsi-panel-v-front-porch = <64>;
				dsi-panel-v-pulse-width = <4>;
				dsi-panel-timing-switch-command = [
					//30hz
					15 00 00 40 00 00 02 6D 03
					39 00 00 40 00 00 06 F0 55 AA 52 08 00
					15 00 00 40 00 00 02 6F DE
					15 00 00 40 00 00 02 BA 04
					15 00 00 40 00 00 02 8C 00
					39 00 00 40 00 00 08 A2 03 01 00 8C 00 00 02
					05 00 00 40 00 00 01 A9
					//fix TE
					15 00 00 40 00 00 02 6F 14
					15 00 00 40 00 00 02 35 00
					15 00 00 40 00 00 02 6F 04
					15 00 00 00 00 00 02 35 00
				];
				dsi-panel-timing-switch-command-state = "dsi_hs_mode";
				dsi-panel-on-command = [
					#include "dsi_panel_o2s_42_02_0a_dsc_cmd_on_common.dtsi"
					//timing config
					15 00 00 40 00 00 02 2F 32
 					//30HZ
					15 00 00 40 00 00 02 6D 03
					39 00 00 40 00 00 06 F0 55 AA 52 08 00
					15 00 00 40 00 00 02 6F DE
					15 00 00 40 00 00 02 BA 04
					15 00 00 40 00 00 02 8C 00
					39 00 00 40 00 00 08 A2 03 01 00 8C 00 00 02
					05 00 00 40 00 00 01 A9
					//fix TE
					15 00 00 40 00 00 02 6F 14
					15 00 00 40 00 00 02 35 00
					15 00 00 40 00 00 02 6F 04
					15 00 00 00 00 00 02 35 00
					15 00 00 00 00 00 02 5A 00
					//51 return in fps
					39 00 00 00 00 00 04 8C 00 00 11
					/* Sleep Out */
					05 00 00 00 78 00 01 11
					39 00 00 40 00 00 06 F0 55 AA 52 08 02
					15 00 00 00 00 00 02 CC 10
					39 00 00 40 00 00 06 F0 55 AA 52 08 09
					15 00 00 40 00 00 02 6F 03
					39 00 00 40 00 00 05 B2 20 24 28 2C
					15 00 00 40 00 00 02 B2 02
					15 00 00 40 00 00 02 DD 01
					15 00 00 40 00 00 02 6F 11
					39 00 00 40 00 00 20 B2 00 40 00 00 00 00 00 00 00 00 00 00 00 F0 FA
										FB FD 03 04 05 05 0D 0A 0A 02 02 02 02 00 00 00
					15 00 00 40 00 00 02 6F 11
					39 00 00 40 00 00 20 B2 01 40 00 00 00 00 00 00 00 00 00 0A 0A 07 06
										08 07 07 07 07 07 07 09 08 0A 05 06 05 00 00 00
					15 00 00 40 00 00 02 6F 11
					39 00 00 40 00 00 20 B2 00 41 00 00 00 00 00 00 00 F4 F4 F4 F4 FA FC
										00 02 0A 0C 0C 0A 0A 0A 0A 00 00 00 00 00 00 00
					15 00 00 40 00 00 02 6F 11
					39 00 00 40 00 00 20 B2 01 41 00 00 00 00 00 00 0D 0D 0D 0D 0F 0D 07
										08 07 07 07 07 06 05 05 05 05 04 03 00 00 00 00
					15 00 00 40 00 00 02 6F 11
					39 00 00 40 00 00 20 B2 00 42 00 00 00 00 00 01 01 01 DF FF FF 01 04
										08 0A 0A 12 0C 0A 0A 0A 0A 05 04 03 01 00 00 00
					15 00 00 40 00 00 02 6F 11
					39 00 00 40 00 00 20 B2 01 42 00 00 00 00 00 00 03 03 0A 0A 0A 0A 0B
										0B 0A 09 09 05 05 05 05 03 03 03 00 00 00 00 00
					15 00 00 40 00 00 02 6F 11
					39 00 00 40 00 00 20 B2 00 43 00 00 00 00 00 01 01 CA D7 03 FD 01 05
										0B 0E 06 06 09 0A 0A 08 04 00 00 00 00 00 00 00
					15 00 00 40 00 00 02 6F 11
					39 00 00 40 00 00 20 B2 01 43 00 00 00 00 00 00 03 F8 08 08 08 08 08
										08 0A 0A 04 04 05 05 05 FE 00 00 00 00 00 00 00
					15 00 00 40 00 00 02 6F 11
					39 00 00 40 00 00 20 B2 00 50 00 00 00 00 00 00 00 00 00 00 F3 F3 F3
										F7 F8 00 03 04 0C 0C 0A 0A 0A 06 06 06 00 00 00
					15 00 00 40 00 00 02 6F 11
					39 00 00 40 00 00 20 B2 01 50 00 00 00 00 00 00 00 00 00 0D 0D 0D 0D
										0A 0A 08 08 08 08 08 0A 0F 10 0F 07 08 00 00 00
					15 00 00 40 00 00 02 6F 11
					39 00 00 40 00 00 20 B2 00 51 00 00 00 00 00 00 00 00 00 00 E8 F0 F5
										FA 00 06 09 0A 09 05 09 02 02 00 00 00 00 00 00
					15 00 00 40 00 00 02 6F 11
					39 00 00 40 00 00 20 B2 01 51 00 00 00 00 00 00 00 00 00 00 0F 0F 09
										0B 0A 0A 07 08 08 08 06 04 02 02 02 01 00 00 00
					15 00 00 40 00 00 02 6F 11
					39 00 00 40 00 00 20 B2 00 52 00 00 00 00 00 00 00 00 00 F0 F0 F2 F8
										00 02 02 04 02 06 04 08 02 00 00 00 00 00 00 00
					15 00 00 40 00 00 02 6F 11
					39 00 00 40 00 00 20 B2 01 52 00 00 00 00 00 00 05 0B 0B 0A 0C 09 06
										06 09 0A 09 08 04 06 04 00 00 00 00 00 00 00 00
					15 00 00 40 00 00 02 6F 11
					39 00 00 40 00 00 20 B2 00 53 00 00 00 00 00 00 00 00 00 00 F0 F9 00
										02 02 01 02 02 06 04 08 02 00 00 00 00 00 00 00
					15 00 00 40 00 00 02 6F 11
					39 00 00 40 00 00 20 B2 01 53 00 00 00 00 00 00 05 0B 0B 0A 0C 07 0B
										0A 09 0A 09 08 04 06 04 00 00 00 00 00 00 00 00
					15 00 00 40 00 00 02 6F 11
					39 00 00 40 00 00 20 B2 00 60 00 00 00 00 00 00 00 00 00 00 DD 00 00
										00 00 00 00 00 00 03 08 04 08 06 06 06 00 00 00
					15 00 00 40 00 00 02 6F 11
					39 00 00 40 00 00 20 B2 01 60 00 00 00 00 00 00 00 00 00 00 11 0D 0D
										0A 0A 08 08 08 08 08 09 0A 12 0F 07 08 00 00 00
					15 00 00 40 00 00 02 6F 11
					39 00 00 40 00 00 20 B2 00 61 00 00 00 00 00 00 00 00 BD DD 00 E0 E6
										EC F5 FD 00 06 06 03 08 08 08 06 06 06 00 00 00
					15 00 00 40 00 00 02 6F 11
					39 00 00 40 00 00 20 B2 01 61 00 00 00 00 00 00 00 00 00 00 11 0D 0D
										0A 0A 08 08 08 08 08 0A 0F 10 0F 07 08 00 00 00
					15 00 00 40 00 00 02 6F 11
					39 00 00 40 00 00 20 B2 00 62 00 00 00 00 00 00 00 00 D7 F5 00 DC EC
										F4 03 06 08 08 06 16 0D 0A 0A 06 08 0A 00 00 00
					15 00 00 40 00 00 02 6F 11
					39 00 00 40 00 00 20 B2 01 62 00 00 00 00 00 00 00 00 0C 0C 0E 0D 0A
										09 0A 08 06 06 06 0F 0A 08 03 00 00 00 00 00 00
					15 00 00 40 00 00 02 6F 11
					39 00 00 40 00 00 20 B2 00 63 00 00 00 00 00 00 00 00 00 C7 EF EF FA
										00 0A 0A 0D 14 14 11 0F 0A 0A 06 08 0A 00 00 00
					15 00 00 40 00 00 02 6F 11
					39 00 00 40 00 00 20 B2 01 63 00 00 00 00 00 00 00 00 00 0D 10 0D 0A
										07 08 07 07 06 0A 07 06 05 00 00 00 00 00 00 00
					15 00 00 40 00 00 02 DD 00
					39 00 00 40 00 00 06 F0 55 AA 52 08 02
					15 00 00 00 00 00 02 CC 00
					//vgl lvd 9V
					39 00 00 40 00 00 06 F0 55 AA 52 08 01
					15 00 00 40 00 00 02 6F 03
					39 00 00 00 00 00 03 C7 E7 50
					//force cmd mode
					39 00 00 40 00 00 04 17 30 00 12
					39 00 00 40 00 00 05 FF AA 55 A5 81
					15 00 00 40 00 00 02 6F 0F
					39 00 00 00 00 00 02 FD 80
					//APL Dimming
					39 00 00 40 00 00 06 F0 55 AA 52 08 00
					15 00 00 40 00 00 02 6F 78
					39 00 00 40 00 00 18 B0 11 00 2A 00 C2 01 DA 03 7C 05 B1 08 80 0B EE 0F FF 05 55 05 56 05 55
					15 00 00 40 00 00 02 6F 6F
					39 00 00 40 00 00 07 B0 02 D0 05 A0 02 D0
					39 00 00 40 00 00 06 F0 55 AA 52 08 08
					//Lv0 1260nits
					39 00 00 40 00 00 17 C1 9D FF DD FF FF DD FF FF DD FF FF DD FF FF ED FF FF FF 7F FF 0D FF
					15 00 00 40 00 00 02 6F 1D
					39 00 00 40 00 00 07 C1 00 FF FF 4F 00 FF
					15 00 00 40 00 00 02 6F 23
					39 00 00 40 00 00 15 C1 0D FF DD FF FF DD FF FF DD FF FF DD FF FF ED FF FF BD 2D 00
					//Lv1 1800nits
					15 00 00 40 00 00 02 6F 37
					39 00 00 40 00 00 15 C1 0D FF DD FF FF DD FF FF DD FF FF DD FF FF ED FF FF FF 7F FF
					15 00 00 40 00 00 02 6F 4B
					39 00 00 40 00 00 15 C1 0D FF DD FF FF DD FF FF DD FF FF DD FF FF ED FF FF DF 7F 11
					39 00 00 40 00 00 2D BA 00 0F 00 1D 00 1D 00 31 00 31 00 53 00 53 01 9B 01 9B 01 9C
								01 9C 05 56 05 56 0F FF 0F FF 15 54 15 54 21 98 21 98 2F FD 2F FD 3F FF
					15 00 00 40 00 00 02 6F 07
					15 00 00 00 00 00 02 51 00
					/* Display On */
					05 00 00 00 00 00 01 29
					39 00 00 40 00 00 06 F0 55 AA 52 08 04
					15 00 00 40 00 00 02 6F 06
					39 00 00 00 00 00 04 CB 00 03 12
					39 00 00 40 00 00 06 F0 55 AA 52 08 08
					39 00 00 40 00 00 0F E1 00 00 00 00 00 00 00 00 00 00 00 00 00 00
					39 00 00 40 00 00 0F E2 00 00 00 00 02 05 08 0A 25 25 27 28 28 28
					39 00 00 00 00 00 0F E3 00 00 00 00 00 00 00 00 10 18 1A 1C 1E 20
					39 00 00 00 00 00 06 F0 55 AA 52 08 0F
				];
				dsi-panel-on-command-state = "dsi_lp_mode";
				mi,dsi-panel-nolp-command = [
					//exit AOD ESD detect 0A
					39 00 00 40 00 00 06 F0 55 AA 52 08 00
					15 00 00 40 00 00 02 6F 19
					39 00 00 40 00 00 05 BE 10 0A 00 9C
					05 00 00 40 00 00 01 38
					39 00 00 00 00 00 03 51 00 23
					//30hz
					15 00 00 40 00 00 02 6D 03
					39 00 00 40 00 00 06 F0 55 AA 52 08 00
					15 00 00 40 00 00 02 6F DE
					15 00 00 40 00 00 02 BA 04
					15 00 00 40 00 00 02 8C 00
					39 00 00 40 00 00 08 A2 03 01 00 8C 00 00 02
					05 00 00 40 00 00 01 A9
					//fix TE
					15 00 00 40 00 00 02 6F 14
					15 00 00 40 00 00 02 35 00
					15 00 00 40 00 00 02 6F 04
					15 00 00 40 00 00 02 35 00
					39 00 00 00 00 00 06 F0 55 AA 52 08 0F
				];
				mi,dsi-panel-nolp-command-update = <0x51 4 2>;
				mi,dsi-panel-nolp-command-state = "dsi_hs_mode";
			};
		normal_24hz_index_05 {
				#include "dsi_panel_o2s_42_02_0a_dsc_cmd_common.dtsi"
				dsi-panel-frame-rate = <24>;
				dsi-panel-te-rate = <120>;
				dsi-panel-base-rate = <120>;
				dsi-panel-vrr-type = <3>;
				dsi-panel-h-front-porch = <12>;
				dsi-panel-h-back-porch = <4>;
				dsi-panel-h-pulse-width = <4>;
				dsi-panel-h-sync-skew = <0>;
				dsi-panel-v-back-porch = <24>;
				dsi-panel-v-front-porch = <64>;
				dsi-panel-v-pulse-width = <4>;
				dsi-panel-timing-switch-command = [
					//24hz
					15 00 00 40 00 00 02 6D 04
					39 00 00 40 00 00 06 F0 55 AA 52 08 00
					15 00 00 40 00 00 02 6F DE
					15 00 00 40 00 00 02 BA 04
					15 00 00 40 00 00 02 8C 00
					39 00 00 40 00 00 08 A2 03 01 00 8C 00 00 02
					05 00 00 40 00 00 01 A9
					//fix TE
					15 00 00 40 00 00 02 6F 14
					15 00 00 40 00 00 02 35 00
					15 00 00 40 00 00 02 6F 04
					15 00 00 00 00 00 02 35 00
				];
				dsi-panel-timing-switch-command-state = "dsi_hs_mode";
				dsi-panel-on-command = [
					#include "dsi_panel_o2s_42_02_0a_dsc_cmd_on_common.dtsi"
					//timing config
					15 00 00 40 00 00 02 2F 32
 					//24HZ
					15 00 00 40 00 00 02 6D 04
					39 00 00 40 00 00 06 F0 55 AA 52 08 00
					15 00 00 40 00 00 02 6F DE
					15 00 00 40 00 00 02 BA 04
					15 00 00 40 00 00 02 8C 00
					39 00 00 40 00 00 08 A2 03 01 00 8C 00 00 02
					05 00 00 40 00 00 01 A9
					//fix TE
					15 00 00 40 00 00 02 6F 14
					15 00 00 40 00 00 02 35 00
					15 00 00 40 00 00 02 6F 04
					15 00 00 40 00 00 02 35 00
					15 00 00 00 00 00 02 5A 00
					//51 return in fps
					39 00 00 00 00 00 04 8C 00 00 11
					/* Sleep Out */
					05 00 00 00 78 00 01 11
					39 00 00 40 00 00 06 F0 55 AA 52 08 02
					15 00 00 00 00 00 02 CC 10
					39 00 00 40 00 00 06 F0 55 AA 52 08 09
					15 00 00 40 00 00 02 6F 03
					39 00 00 40 00 00 05 B2 20 24 28 2C
					15 00 00 40 00 00 02 B2 02
					15 00 00 40 00 00 02 DD 01
					15 00 00 40 00 00 02 6F 11
					39 00 00 40 00 00 20 B2 00 40 00 00 00 00 00 00 00 00 00 00 00 F0 FA
										FB FD 03 04 05 05 0D 0A 0A 02 02 02 02 00 00 00
					15 00 00 40 00 00 02 6F 11
					39 00 00 40 00 00 20 B2 01 40 00 00 00 00 00 00 00 00 00 0A 0A 07 06
										08 07 07 07 07 07 07 09 08 0A 05 06 05 00 00 00
					15 00 00 40 00 00 02 6F 11
					39 00 00 40 00 00 20 B2 00 41 00 00 00 00 00 00 00 F4 F4 F4 F4 FA FC
										00 02 0A 0C 0C 0A 0A 0A 0A 00 00 00 00 00 00 00
					15 00 00 40 00 00 02 6F 11
					39 00 00 40 00 00 20 B2 01 41 00 00 00 00 00 00 0D 0D 0D 0D 0F 0D 07
										08 07 07 07 07 06 05 05 05 05 04 03 00 00 00 00
					15 00 00 40 00 00 02 6F 11
					39 00 00 40 00 00 20 B2 00 42 00 00 00 00 00 01 01 01 DF FF FF 01 04
										08 0A 0A 12 0C 0A 0A 0A 0A 05 04 03 01 00 00 00
					15 00 00 40 00 00 02 6F 11
					39 00 00 40 00 00 20 B2 01 42 00 00 00 00 00 00 03 03 0A 0A 0A 0A 0B
										0B 0A 09 09 05 05 05 05 03 03 03 00 00 00 00 00
					15 00 00 40 00 00 02 6F 11
					39 00 00 40 00 00 20 B2 00 43 00 00 00 00 00 01 01 CA D7 03 FD 01 05
										0B 0E 06 06 09 0A 0A 08 04 00 00 00 00 00 00 00
					15 00 00 40 00 00 02 6F 11
					39 00 00 40 00 00 20 B2 01 43 00 00 00 00 00 00 03 F8 08 08 08 08 08
										08 0A 0A 04 04 05 05 05 FE 00 00 00 00 00 00 00
					15 00 00 40 00 00 02 6F 11
					39 00 00 40 00 00 20 B2 00 50 00 00 00 00 00 00 00 00 00 00 F3 F3 F3
										F7 F8 00 03 04 0C 0C 0A 0A 0A 06 06 06 00 00 00
					15 00 00 40 00 00 02 6F 11
					39 00 00 40 00 00 20 B2 01 50 00 00 00 00 00 00 00 00 00 0D 0D 0D 0D
										0A 0A 08 08 08 08 08 0A 0F 10 0F 07 08 00 00 00
					15 00 00 40 00 00 02 6F 11
					39 00 00 40 00 00 20 B2 00 51 00 00 00 00 00 00 00 00 00 00 E8 F0 F5
										FA 00 06 09 0A 09 05 09 02 02 00 00 00 00 00 00
					15 00 00 40 00 00 02 6F 11
					39 00 00 40 00 00 20 B2 01 51 00 00 00 00 00 00 00 00 00 00 0F 0F 09
										0B 0A 0A 07 08 08 08 06 04 02 02 02 01 00 00 00
					15 00 00 40 00 00 02 6F 11
					39 00 00 40 00 00 20 B2 00 52 00 00 00 00 00 00 00 00 00 F0 F0 F2 F8
										00 02 02 04 02 06 04 08 02 00 00 00 00 00 00 00
					15 00 00 40 00 00 02 6F 11
					39 00 00 40 00 00 20 B2 01 52 00 00 00 00 00 00 05 0B 0B 0A 0C 09 06
										06 09 0A 09 08 04 06 04 00 00 00 00 00 00 00 00
					15 00 00 40 00 00 02 6F 11
					39 00 00 40 00 00 20 B2 00 53 00 00 00 00 00 00 00 00 00 00 F0 F9 00
										02 02 01 02 02 06 04 08 02 00 00 00 00 00 00 00
					15 00 00 40 00 00 02 6F 11
					39 00 00 40 00 00 20 B2 01 53 00 00 00 00 00 00 05 0B 0B 0A 0C 07 0B
										0A 09 0A 09 08 04 06 04 00 00 00 00 00 00 00 00
					15 00 00 40 00 00 02 6F 11
					39 00 00 40 00 00 20 B2 00 60 00 00 00 00 00 00 00 00 00 00 DD 00 00
										00 00 00 00 00 00 03 08 04 08 06 06 06 00 00 00
					15 00 00 40 00 00 02 6F 11
					39 00 00 40 00 00 20 B2 01 60 00 00 00 00 00 00 00 00 00 00 11 0D 0D
										0A 0A 08 08 08 08 08 09 0A 12 0F 07 08 00 00 00
					15 00 00 40 00 00 02 6F 11
					39 00 00 40 00 00 20 B2 00 61 00 00 00 00 00 00 00 00 BD DD 00 E0 E6
										EC F5 FD 00 06 06 03 08 08 08 06 06 06 00 00 00
					15 00 00 40 00 00 02 6F 11
					39 00 00 40 00 00 20 B2 01 61 00 00 00 00 00 00 00 00 00 00 11 0D 0D
										0A 0A 08 08 08 08 08 0A 0F 10 0F 07 08 00 00 00
					15 00 00 40 00 00 02 6F 11
					39 00 00 40 00 00 20 B2 00 62 00 00 00 00 00 00 00 00 D7 F5 00 DC EC
										F4 03 06 08 08 06 16 0D 0A 0A 06 08 0A 00 00 00
					15 00 00 40 00 00 02 6F 11
					39 00 00 40 00 00 20 B2 01 62 00 00 00 00 00 00 00 00 0C 0C 0E 0D 0A
										09 0A 08 06 06 06 0F 0A 08 03 00 00 00 00 00 00
					15 00 00 40 00 00 02 6F 11
					39 00 00 40 00 00 20 B2 00 63 00 00 00 00 00 00 00 00 00 C7 EF EF FA
										00 0A 0A 0D 14 14 11 0F 0A 0A 06 08 0A 00 00 00
					15 00 00 40 00 00 02 6F 11
					39 00 00 40 00 00 20 B2 01 63 00 00 00 00 00 00 00 00 00 0D 10 0D 0A
										07 08 07 07 06 0A 07 06 05 00 00 00 00 00 00 00
					15 00 00 40 00 00 02 DD 00
					39 00 00 40 00 00 06 F0 55 AA 52 08 02
					15 00 00 00 00 00 02 CC 00
					//vgl lvd 9V
					39 00 00 40 00 00 06 F0 55 AA 52 08 01
					15 00 00 40 00 00 02 6F 03
					39 00 00 00 00 00 03 C7 E7 50
					//force cmd mode
					39 00 00 40 00 00 04 17 30 00 12
					39 00 00 40 00 00 05 FF AA 55 A5 81
					15 00 00 40 00 00 02 6F 0F
					39 00 00 00 00 00 02 FD 80
					//APL Dimming
					39 00 00 40 00 00 06 F0 55 AA 52 08 00
					15 00 00 40 00 00 02 6F 78
					39 00 00 40 00 00 18 B0 11 00 2A 00 C2 01 DA 03 7C 05 B1 08 80 0B EE 0F FF 05 55 05 56 05 55
					15 00 00 40 00 00 02 6F 6F
					39 00 00 40 00 00 07 B0 02 D0 05 A0 02 D0
					39 00 00 40 00 00 06 F0 55 AA 52 08 08
					//Lv0 1260nits
					39 00 00 40 00 00 17 C1 9D FF DD FF FF DD FF FF DD FF FF DD FF FF ED FF FF FF 7F FF 0D FF
					15 00 00 40 00 00 02 6F 1D
					39 00 00 40 00 00 07 C1 00 FF FF 4F 00 FF
					15 00 00 40 00 00 02 6F 23
					39 00 00 40 00 00 15 C1 0D FF DD FF FF DD FF FF DD FF FF DD FF FF ED FF FF BD 2D 00
					//Lv1 1800nits
					15 00 00 40 00 00 02 6F 37
					39 00 00 40 00 00 15 C1 0D FF DD FF FF DD FF FF DD FF FF DD FF FF ED FF FF FF 7F FF
					15 00 00 40 00 00 02 6F 4B
					39 00 00 40 00 00 15 C1 0D FF DD FF FF DD FF FF DD FF FF DD FF FF ED FF FF DF 7F 11
					39 00 00 40 00 00 2D BA 00 0F 00 1D 00 1D 00 31 00 31 00 53 00 53 01 9B 01 9B 01 9C
								01 9C 05 56 05 56 0F FF 0F FF 15 54 15 54 21 98 21 98 2F FD 2F FD 3F FF
					15 00 00 40 00 00 02 6F 07
					15 00 00 00 00 00 02 51 00
					/* Display On */
					05 00 00 00 00 00 01 29
					39 00 00 40 00 00 06 F0 55 AA 52 08 04
					15 00 00 40 00 00 02 6F 06
					39 00 00 00 00 00 04 CB 00 03 12
					39 00 00 40 00 00 06 F0 55 AA 52 08 08
					39 00 00 40 00 00 0F E1 00 00 00 00 00 00 00 00 00 00 00 00 00 00
					39 00 00 40 00 00 0F E2 00 00 00 00 02 05 08 0A 25 25 27 28 28 28
					39 00 00 00 00 00 0F E3 00 00 00 00 00 00 00 00 10 18 1A 1C 1E 20
					39 00 00 00 00 00 06 F0 55 AA 52 08 0F
				];
				dsi-panel-on-command-state = "dsi_lp_mode";
				mi,dsi-panel-nolp-command = [
					//exit AOD ESD detect 0A
					39 00 00 40 00 00 06 F0 55 AA 52 08 00
					15 00 00 40 00 00 02 6F 19
					39 00 00 40 00 00 05 BE 10 0A 00 9C
					05 00 00 40 00 00 01 38
					39 00 00 00 00 00 03 51 00 23
					//24hz
					15 00 00 40 00 00 02 6D 04
					39 00 00 40 00 00 06 F0 55 AA 52 08 00
					15 00 00 40 00 00 02 6F DE
					15 00 00 40 00 00 02 BA 04
					15 00 00 40 00 00 02 8C 00
					39 00 00 40 00 00 08 A2 03 01 00 8C 00 00 02
					05 00 00 40 00 00 01 A9
					//fix TE
					15 00 00 40 00 00 02 6F 14
					15 00 00 40 00 00 02 35 00
					15 00 00 40 00 00 02 6F 04
					15 00 00 40 00 00 02 35 00
					39 00 00 00 00 00 06 F0 55 AA 52 08 0F
				];
				mi,dsi-panel-nolp-command-update = <0x51 4 2>;
				mi,dsi-panel-nolp-command-state = "dsi_hs_mode";
			};
		idle_60_to_10hz_index_06 {
				#include "dsi_panel_o2s_42_02_0a_dsc_cmd_common.dtsi"
				dsi-panel-frame-rate = <60>;
				dsi-panel-te-rate = <120>;
				dsi-panel-base-rate = <120>;
				dsi-panel-vrr-type = <3>;
				/* ---------------------------- */
				/* | 15 - 14 | 13 - 7 | 6 - 0 | */
				/* ---------------------------- */
				/* |   mode  | sf fps | min fps| */
				/* ---------------------------- -*/
				/* mode: 1 idle, 2 auto, 3 qsync */
				/*   1 << 14 | 60 << 7 | 10     */
				dsi-panel-h-sync-skew  = <24074>;
				/* mode: 0 normal, 1 idle, 2 auto, 3 qsync, 4 diff, 5 test */
				mi,dsi-panel-ddic-mode = "idle";
				mi,dsi-panel-sf-framerate = <60>;
				mi,dsi-panel-ddic-min-framerate = <10>;
				dsi-panel-h-front-porch = <12>;
				dsi-panel-h-back-porch = <4>;
				dsi-panel-h-pulse-width = <4>;
				dsi-panel-v-back-porch = <24>;
				dsi-panel-v-front-porch = <64>;
				dsi-panel-v-pulse-width = <4>;
				dsi-panel-timing-switch-command = [
					//10hz
					15 00 00 40 00 00 02 6D 08
					39 00 00 40 00 00 06 F0 55 AA 52 08 00
					15 00 00 40 00 00 02 6F DE
					15 00 00 40 00 00 02 BA 00
					15 00 00 00 00 00 02 8C 00
					//fix TE
					15 00 00 40 00 00 02 6F 14
					15 00 00 40 00 00 02 35 00
					15 00 00 40 00 00 02 6F 04
					15 00 00 00 00 00 02 35 00
				];
				dsi-panel-timing-switch-command-state = "dsi_hs_mode";
				dsi-panel-on-command = [
					#include "dsi_panel_o2s_42_02_0a_dsc_cmd_on_common.dtsi"
					//timing config
					15 00 00 40 00 00 02 2F 32
 					//10HZ
					15 00 00 40 00 00 02 6D 08
					39 00 00 40 00 00 06 F0 55 AA 52 08 00
					15 00 00 40 00 00 02 6F DE
					15 00 00 40 00 00 02 BA 00
					15 00 00 00 00 00 02 8C 00
					//fix TE
					15 00 00 40 00 00 02 6F 14
					15 00 00 40 00 00 02 35 00
					15 00 00 40 00 00 02 6F 04
					15 00 00 40 00 00 02 35 00
					15 00 00 00 00 00 02 5A 00
					//51 return in fps
					39 00 00 00 00 00 04 8C 00 00 11
					/* Sleep Out */
					05 00 00 00 78 00 01 11
					39 00 00 40 00 00 06 F0 55 AA 52 08 02
					15 00 00 00 00 00 02 CC 10
					39 00 00 40 00 00 06 F0 55 AA 52 08 09
					15 00 00 40 00 00 02 6F 03
					39 00 00 40 00 00 05 B2 20 24 28 2C
					15 00 00 40 00 00 02 B2 02
					15 00 00 40 00 00 02 DD 01
					15 00 00 40 00 00 02 6F 11
					39 00 00 40 00 00 20 B2 00 40 00 00 00 00 00 00 00 00 00 00 00 F0 FA
										FB FD 03 04 05 05 0D 0A 0A 02 02 02 02 00 00 00
					15 00 00 40 00 00 02 6F 11
					39 00 00 40 00 00 20 B2 01 40 00 00 00 00 00 00 00 00 00 0A 0A 07 06
										08 07 07 07 07 07 07 09 08 0A 05 06 05 00 00 00
					15 00 00 40 00 00 02 6F 11
					39 00 00 40 00 00 20 B2 00 41 00 00 00 00 00 00 00 F4 F4 F4 F4 FA FC
										00 02 0A 0C 0C 0A 0A 0A 0A 00 00 00 00 00 00 00
					15 00 00 40 00 00 02 6F 11
					39 00 00 40 00 00 20 B2 01 41 00 00 00 00 00 00 0D 0D 0D 0D 0F 0D 07
										08 07 07 07 07 06 05 05 05 05 04 03 00 00 00 00
					15 00 00 40 00 00 02 6F 11
					39 00 00 40 00 00 20 B2 00 42 00 00 00 00 00 01 01 01 DF FF FF 01 04
										08 0A 0A 12 0C 0A 0A 0A 0A 05 04 03 01 00 00 00
					15 00 00 40 00 00 02 6F 11
					39 00 00 40 00 00 20 B2 01 42 00 00 00 00 00 00 03 03 0A 0A 0A 0A 0B
										0B 0A 09 09 05 05 05 05 03 03 03 00 00 00 00 00
					15 00 00 40 00 00 02 6F 11
					39 00 00 40 00 00 20 B2 00 43 00 00 00 00 00 01 01 CA D7 03 FD 01 05
										0B 0E 06 06 09 0A 0A 08 04 00 00 00 00 00 00 00
					15 00 00 40 00 00 02 6F 11
					39 00 00 40 00 00 20 B2 01 43 00 00 00 00 00 00 03 F8 08 08 08 08 08
										08 0A 0A 04 04 05 05 05 FE 00 00 00 00 00 00 00
					15 00 00 40 00 00 02 6F 11
					39 00 00 40 00 00 20 B2 00 50 00 00 00 00 00 00 00 00 00 00 F3 F3 F3
										F7 F8 00 03 04 0C 0C 0A 0A 0A 06 06 06 00 00 00
					15 00 00 40 00 00 02 6F 11
					39 00 00 40 00 00 20 B2 01 50 00 00 00 00 00 00 00 00 00 0D 0D 0D 0D
										0A 0A 08 08 08 08 08 0A 0F 10 0F 07 08 00 00 00
					15 00 00 40 00 00 02 6F 11
					39 00 00 40 00 00 20 B2 00 51 00 00 00 00 00 00 00 00 00 00 E8 F0 F5
										FA 00 06 09 0A 09 05 09 02 02 00 00 00 00 00 00
					15 00 00 40 00 00 02 6F 11
					39 00 00 40 00 00 20 B2 01 51 00 00 00 00 00 00 00 00 00 00 0F 0F 09
										0B 0A 0A 07 08 08 08 06 04 02 02 02 01 00 00 00
					15 00 00 40 00 00 02 6F 11
					39 00 00 40 00 00 20 B2 00 52 00 00 00 00 00 00 00 00 00 F0 F0 F2 F8
										00 02 02 04 02 06 04 08 02 00 00 00 00 00 00 00
					15 00 00 40 00 00 02 6F 11
					39 00 00 40 00 00 20 B2 01 52 00 00 00 00 00 00 05 0B 0B 0A 0C 09 06
										06 09 0A 09 08 04 06 04 00 00 00 00 00 00 00 00
					15 00 00 40 00 00 02 6F 11
					39 00 00 40 00 00 20 B2 00 53 00 00 00 00 00 00 00 00 00 00 F0 F9 00
										02 02 01 02 02 06 04 08 02 00 00 00 00 00 00 00
					15 00 00 40 00 00 02 6F 11
					39 00 00 40 00 00 20 B2 01 53 00 00 00 00 00 00 05 0B 0B 0A 0C 07 0B
										0A 09 0A 09 08 04 06 04 00 00 00 00 00 00 00 00
					15 00 00 40 00 00 02 6F 11
					39 00 00 40 00 00 20 B2 00 60 00 00 00 00 00 00 00 00 00 00 DD 00 00
										00 00 00 00 00 00 03 08 04 08 06 06 06 00 00 00
					15 00 00 40 00 00 02 6F 11
					39 00 00 40 00 00 20 B2 01 60 00 00 00 00 00 00 00 00 00 00 11 0D 0D
										0A 0A 08 08 08 08 08 09 0A 12 0F 07 08 00 00 00
					15 00 00 40 00 00 02 6F 11
					39 00 00 40 00 00 20 B2 00 61 00 00 00 00 00 00 00 00 BD DD 00 E0 E6
										EC F5 FD 00 06 06 03 08 08 08 06 06 06 00 00 00
					15 00 00 40 00 00 02 6F 11
					39 00 00 40 00 00 20 B2 01 61 00 00 00 00 00 00 00 00 00 00 11 0D 0D
										0A 0A 08 08 08 08 08 0A 0F 10 0F 07 08 00 00 00
					15 00 00 40 00 00 02 6F 11
					39 00 00 40 00 00 20 B2 00 62 00 00 00 00 00 00 00 00 D7 F5 00 DC EC
										F4 03 06 08 08 06 16 0D 0A 0A 06 08 0A 00 00 00
					15 00 00 40 00 00 02 6F 11
					39 00 00 40 00 00 20 B2 01 62 00 00 00 00 00 00 00 00 0C 0C 0E 0D 0A
										09 0A 08 06 06 06 0F 0A 08 03 00 00 00 00 00 00
					15 00 00 40 00 00 02 6F 11
					39 00 00 40 00 00 20 B2 00 63 00 00 00 00 00 00 00 00 00 C7 EF EF FA
										00 0A 0A 0D 14 14 11 0F 0A 0A 06 08 0A 00 00 00
					15 00 00 40 00 00 02 6F 11
					39 00 00 40 00 00 20 B2 01 63 00 00 00 00 00 00 00 00 00 0D 10 0D 0A
										07 08 07 07 06 0A 07 06 05 00 00 00 00 00 00 00
					15 00 00 40 00 00 02 DD 00
					39 00 00 40 00 00 06 F0 55 AA 52 08 02
					15 00 00 00 00 00 02 CC 00
					//vgl lvd 9V
					39 00 00 40 00 00 06 F0 55 AA 52 08 01
					15 00 00 40 00 00 02 6F 03
					39 00 00 00 00 00 03 C7 E7 50
					//force cmd mode
					39 00 00 40 00 00 04 17 30 00 12
					39 00 00 40 00 00 05 FF AA 55 A5 81
					15 00 00 40 00 00 02 6F 0F
					39 00 00 00 00 00 02 FD 80
					//APL Dimming
					39 00 00 40 00 00 06 F0 55 AA 52 08 00
					15 00 00 40 00 00 02 6F 78
					39 00 00 40 00 00 18 B0 11 00 2A 00 C2 01 DA 03 7C 05 B1 08 80 0B EE 0F FF 05 55 05 56 05 55
					15 00 00 40 00 00 02 6F 6F
					39 00 00 40 00 00 07 B0 02 D0 05 A0 02 D0
					39 00 00 40 00 00 06 F0 55 AA 52 08 08
					//Lv0 1260nits
					39 00 00 40 00 00 17 C1 9D FF DD FF FF DD FF FF DD FF FF DD FF FF ED FF FF FF 7F FF 0D FF
					15 00 00 40 00 00 02 6F 1D
					39 00 00 40 00 00 07 C1 00 FF FF 4F 00 FF
					15 00 00 40 00 00 02 6F 23
					39 00 00 40 00 00 15 C1 0D FF DD FF FF DD FF FF DD FF FF DD FF FF ED FF FF BD 2D 00
					//Lv1 1800nits
					15 00 00 40 00 00 02 6F 37
					39 00 00 40 00 00 15 C1 0D FF DD FF FF DD FF FF DD FF FF DD FF FF ED FF FF FF 7F FF
					15 00 00 40 00 00 02 6F 4B
					39 00 00 40 00 00 15 C1 0D FF DD FF FF DD FF FF DD FF FF DD FF FF ED FF FF DF 7F 11
					39 00 00 40 00 00 2D BA 00 0F 00 1D 00 1D 00 31 00 31 00 53 00 53 01 9B 01 9B 01 9C
								01 9C 05 56 05 56 0F FF 0F FF 15 54 15 54 21 98 21 98 2F FD 2F FD 3F FF
					15 00 00 40 00 00 02 6F 07
					15 00 00 00 00 00 02 51 00
					/* Display On */
					05 00 00 00 00 00 01 29
					39 00 00 40 00 00 06 F0 55 AA 52 08 04
					15 00 00 40 00 00 02 6F 06
					39 00 00 00 00 00 04 CB 00 03 12
					39 00 00 40 00 00 06 F0 55 AA 52 08 08
					39 00 00 40 00 00 0F E1 00 00 00 00 00 00 00 00 00 00 00 00 00 00
					39 00 00 40 00 00 0F E2 00 00 00 00 02 05 08 0A 25 25 27 28 28 28
					39 00 00 00 00 00 0F E3 00 00 00 00 00 00 00 00 10 18 1A 1C 1E 20
					39 00 00 00 00 00 06 F0 55 AA 52 08 0F
				];
				dsi-panel-on-command-state = "dsi_lp_mode";
				mi,dsi-panel-nolp-command = [
					//exit AOD ESD detect 0A
					39 00 00 40 00 00 06 F0 55 AA 52 08 00
					15 00 00 40 00 00 02 6F 19
					39 00 00 40 00 00 05 BE 10 0A 00 9C
					05 00 00 40 00 00 01 38
					39 00 00 00 00 00 03 51 00 23
					//10hz
					15 00 00 40 00 00 02 6D 08
					39 00 00 40 00 00 06 F0 55 AA 52 08 00
					15 00 00 40 00 00 02 6F DE
					15 00 00 40 00 00 02 BA 00
					15 00 00 00 00 00 02 8C 00
					//fix TE
					15 00 00 40 00 00 02 6F 14
					15 00 00 40 00 00 02 35 00
					15 00 00 40 00 00 02 6F 04
					15 00 00 40 00 00 02 35 00
					39 00 00 00 00 00 06 F0 55 AA 52 08 0F
				];
				mi,dsi-panel-nolp-command-update = <0x51 4 2>;
				mi,dsi-panel-nolp-command-state = "dsi_hs_mode";
			};
		idle_60_to_1hz_index_07 {
				#include "dsi_panel_o2s_42_02_0a_dsc_cmd_common.dtsi"
				dsi-panel-frame-rate = <60>;
				dsi-panel-te-rate = <120>;
				dsi-panel-base-rate = <120>;
				dsi-panel-vrr-type = <3>;
				/* ---------------------------- */
				/* | 15 - 14 | 13 - 7 | 6 - 0 | */
				/* ---------------------------- */
				/* |   mode  | sf fps | min fps| */
				/* ---------------------------- -*/
				/* mode: 1 idle, 2 auto, 3 qsync */
				/*   1 << 14 | 60 << 7 | 1     */
				dsi-panel-h-sync-skew  = <24065>;
				/* mode: 0 normal, 1 idle, 2 auto, 3 qsync, 4 diff, 5 test */
				mi,dsi-panel-ddic-mode = "idle";
				mi,dsi-panel-sf-framerate = <60>;
				mi,dsi-panel-ddic-min-framerate = <1>;
				dsi-panel-h-front-porch = <12>;
				dsi-panel-h-back-porch = <4>;
				dsi-panel-h-pulse-width = <4>;
				dsi-panel-v-back-porch = <24>;
				dsi-panel-v-front-porch = <64>;
				dsi-panel-v-pulse-width = <4>;
				dsi-panel-timing-switch-command = [
					//1hz
					15 00 00 40 00 00 02 6D 09
					39 00 00 40 00 00 06 F0 55 AA 52 08 00
					15 00 00 40 00 00 02 6F DE
					15 00 00 40 00 00 02 BA 00
					15 00 00 00 00 00 02 8C 00
					//fix TE
					15 00 00 40 00 00 02 6F 14
					15 00 00 40 00 00 02 35 00
					15 00 00 40 00 00 02 6F 04
					15 00 00 00 00 00 02 35 00
				];
				dsi-panel-timing-switch-command-state = "dsi_hs_mode";
				dsi-panel-on-command = [
					#include "dsi_panel_o2s_42_02_0a_dsc_cmd_on_common.dtsi"
					//timing config
					15 00 00 40 00 00 02 2F 32
 					//1HZ
					15 00 00 40 00 00 02 6D 09
					39 00 00 40 00 00 06 F0 55 AA 52 08 00
					15 00 00 40 00 00 02 6F DE
					15 00 00 40 00 00 02 BA 00
					15 00 00 00 00 00 02 8C 00
					//fix TE
					15 00 00 40 00 00 02 6F 14
					15 00 00 40 00 00 02 35 00
					15 00 00 40 00 00 02 6F 04
					15 00 00 40 00 00 02 35 00
					15 00 00 00 00 00 02 5A 00
					//51 return in fps
					39 00 00 00 00 00 04 8C 00 00 11
					/* Sleep Out */
					05 00 00 00 78 00 01 11
					39 00 00 40 00 00 06 F0 55 AA 52 08 02
					15 00 00 00 00 00 02 CC 10
					39 00 00 40 00 00 06 F0 55 AA 52 08 09
					15 00 00 40 00 00 02 6F 03
					39 00 00 40 00 00 05 B2 20 24 28 2C
					15 00 00 40 00 00 02 B2 02
					15 00 00 40 00 00 02 DD 01
					15 00 00 40 00 00 02 6F 11
					39 00 00 40 00 00 20 B2 00 40 00 00 00 00 00 00 00 00 00 00 00 F0 FA
										FB FD 03 04 05 05 0D 0A 0A 02 02 02 02 00 00 00
					15 00 00 40 00 00 02 6F 11
					39 00 00 40 00 00 20 B2 01 40 00 00 00 00 00 00 00 00 00 0A 0A 07 06
										08 07 07 07 07 07 07 09 08 0A 05 06 05 00 00 00
					15 00 00 40 00 00 02 6F 11
					39 00 00 40 00 00 20 B2 00 41 00 00 00 00 00 00 00 F4 F4 F4 F4 FA FC
										00 02 0A 0C 0C 0A 0A 0A 0A 00 00 00 00 00 00 00
					15 00 00 40 00 00 02 6F 11
					39 00 00 40 00 00 20 B2 01 41 00 00 00 00 00 00 0D 0D 0D 0D 0F 0D 07
										08 07 07 07 07 06 05 05 05 05 04 03 00 00 00 00
					15 00 00 40 00 00 02 6F 11
					39 00 00 40 00 00 20 B2 00 42 00 00 00 00 00 01 01 01 DF FF FF 01 04
										08 0A 0A 12 0C 0A 0A 0A 0A 05 04 03 01 00 00 00
					15 00 00 40 00 00 02 6F 11
					39 00 00 40 00 00 20 B2 01 42 00 00 00 00 00 00 03 03 0A 0A 0A 0A 0B
										0B 0A 09 09 05 05 05 05 03 03 03 00 00 00 00 00
					15 00 00 40 00 00 02 6F 11
					39 00 00 40 00 00 20 B2 00 43 00 00 00 00 00 01 01 CA D7 03 FD 01 05
										0B 0E 06 06 09 0A 0A 08 04 00 00 00 00 00 00 00
					15 00 00 40 00 00 02 6F 11
					39 00 00 40 00 00 20 B2 01 43 00 00 00 00 00 00 03 F8 08 08 08 08 08
										08 0A 0A 04 04 05 05 05 FE 00 00 00 00 00 00 00
					15 00 00 40 00 00 02 6F 11
					39 00 00 40 00 00 20 B2 00 50 00 00 00 00 00 00 00 00 00 00 F3 F3 F3
										F7 F8 00 03 04 0C 0C 0A 0A 0A 06 06 06 00 00 00
					15 00 00 40 00 00 02 6F 11
					39 00 00 40 00 00 20 B2 01 50 00 00 00 00 00 00 00 00 00 0D 0D 0D 0D
										0A 0A 08 08 08 08 08 0A 0F 10 0F 07 08 00 00 00
					15 00 00 40 00 00 02 6F 11
					39 00 00 40 00 00 20 B2 00 51 00 00 00 00 00 00 00 00 00 00 E8 F0 F5
										FA 00 06 09 0A 09 05 09 02 02 00 00 00 00 00 00
					15 00 00 40 00 00 02 6F 11
					39 00 00 40 00 00 20 B2 01 51 00 00 00 00 00 00 00 00 00 00 0F 0F 09
										0B 0A 0A 07 08 08 08 06 04 02 02 02 01 00 00 00
					15 00 00 40 00 00 02 6F 11
					39 00 00 40 00 00 20 B2 00 52 00 00 00 00 00 00 00 00 00 F0 F0 F2 F8
										00 02 02 04 02 06 04 08 02 00 00 00 00 00 00 00
					15 00 00 40 00 00 02 6F 11
					39 00 00 40 00 00 20 B2 01 52 00 00 00 00 00 00 05 0B 0B 0A 0C 09 06
										06 09 0A 09 08 04 06 04 00 00 00 00 00 00 00 00
					15 00 00 40 00 00 02 6F 11
					39 00 00 40 00 00 20 B2 00 53 00 00 00 00 00 00 00 00 00 00 F0 F9 00
										02 02 01 02 02 06 04 08 02 00 00 00 00 00 00 00
					15 00 00 40 00 00 02 6F 11
					39 00 00 40 00 00 20 B2 01 53 00 00 00 00 00 00 05 0B 0B 0A 0C 07 0B
										0A 09 0A 09 08 04 06 04 00 00 00 00 00 00 00 00
					15 00 00 40 00 00 02 6F 11
					39 00 00 40 00 00 20 B2 00 60 00 00 00 00 00 00 00 00 00 00 DD 00 00
										00 00 00 00 00 00 03 08 04 08 06 06 06 00 00 00
					15 00 00 40 00 00 02 6F 11
					39 00 00 40 00 00 20 B2 01 60 00 00 00 00 00 00 00 00 00 00 11 0D 0D
										0A 0A 08 08 08 08 08 09 0A 12 0F 07 08 00 00 00
					15 00 00 40 00 00 02 6F 11
					39 00 00 40 00 00 20 B2 00 61 00 00 00 00 00 00 00 00 BD DD 00 E0 E6
										EC F5 FD 00 06 06 03 08 08 08 06 06 06 00 00 00
					15 00 00 40 00 00 02 6F 11
					39 00 00 40 00 00 20 B2 01 61 00 00 00 00 00 00 00 00 00 00 11 0D 0D
										0A 0A 08 08 08 08 08 0A 0F 10 0F 07 08 00 00 00
					15 00 00 40 00 00 02 6F 11
					39 00 00 40 00 00 20 B2 00 62 00 00 00 00 00 00 00 00 D7 F5 00 DC EC
										F4 03 06 08 08 06 16 0D 0A 0A 06 08 0A 00 00 00
					15 00 00 40 00 00 02 6F 11
					39 00 00 40 00 00 20 B2 01 62 00 00 00 00 00 00 00 00 0C 0C 0E 0D 0A
										09 0A 08 06 06 06 0F 0A 08 03 00 00 00 00 00 00
					15 00 00 40 00 00 02 6F 11
					39 00 00 40 00 00 20 B2 00 63 00 00 00 00 00 00 00 00 00 C7 EF EF FA
										00 0A 0A 0D 14 14 11 0F 0A 0A 06 08 0A 00 00 00
					15 00 00 40 00 00 02 6F 11
					39 00 00 40 00 00 20 B2 01 63 00 00 00 00 00 00 00 00 00 0D 10 0D 0A
										07 08 07 07 06 0A 07 06 05 00 00 00 00 00 00 00
					15 00 00 40 00 00 02 DD 00
					39 00 00 40 00 00 06 F0 55 AA 52 08 02
					15 00 00 00 00 00 02 CC 00
					//vgl lvd 9V
					39 00 00 40 00 00 06 F0 55 AA 52 08 01
					15 00 00 40 00 00 02 6F 03
					39 00 00 00 00 00 03 C7 E7 50
					//force cmd mode
					39 00 00 40 00 00 04 17 30 00 12
					39 00 00 40 00 00 05 FF AA 55 A5 81
					15 00 00 40 00 00 02 6F 0F
					39 00 00 00 00 00 02 FD 80
					//APL Dimming
					39 00 00 40 00 00 06 F0 55 AA 52 08 00
					15 00 00 40 00 00 02 6F 78
					39 00 00 40 00 00 18 B0 11 00 2A 00 C2 01 DA 03 7C 05 B1 08 80 0B EE 0F FF 05 55 05 56 05 55
					15 00 00 40 00 00 02 6F 6F
					39 00 00 40 00 00 07 B0 02 D0 05 A0 02 D0
					39 00 00 40 00 00 06 F0 55 AA 52 08 08
					//Lv0 1260nits
					39 00 00 40 00 00 17 C1 9D FF DD FF FF DD FF FF DD FF FF DD FF FF ED FF FF FF 7F FF 0D FF
					15 00 00 40 00 00 02 6F 1D
					39 00 00 40 00 00 07 C1 00 FF FF 4F 00 FF
					15 00 00 40 00 00 02 6F 23
					39 00 00 40 00 00 15 C1 0D FF DD FF FF DD FF FF DD FF FF DD FF FF ED FF FF BD 2D 00
					//Lv1 1800nits
					15 00 00 40 00 00 02 6F 37
					39 00 00 40 00 00 15 C1 0D FF DD FF FF DD FF FF DD FF FF DD FF FF ED FF FF FF 7F FF
					15 00 00 40 00 00 02 6F 4B
					39 00 00 40 00 00 15 C1 0D FF DD FF FF DD FF FF DD FF FF DD FF FF ED FF FF DF 7F 11
					39 00 00 40 00 00 2D BA 00 0F 00 1D 00 1D 00 31 00 31 00 53 00 53 01 9B 01 9B 01 9C
								01 9C 05 56 05 56 0F FF 0F FF 15 54 15 54 21 98 21 98 2F FD 2F FD 3F FF
					15 00 00 40 00 00 02 6F 07
					15 00 00 00 00 00 02 51 00
					/* Display On */
					05 00 00 00 00 00 01 29
					39 00 00 40 00 00 06 F0 55 AA 52 08 04
					15 00 00 40 00 00 02 6F 06
					39 00 00 00 00 00 04 CB 00 03 12
					39 00 00 40 00 00 06 F0 55 AA 52 08 08
					39 00 00 40 00 00 0F E1 00 00 00 00 00 00 00 00 00 00 00 00 00 00
					39 00 00 40 00 00 0F E2 00 00 00 00 02 05 08 0A 25 25 27 28 28 28
					39 00 00 00 00 00 0F E3 00 00 00 00 00 00 00 00 10 18 1A 1C 1E 20
					39 00 00 00 00 00 06 F0 55 AA 52 08 0F
				];
				dsi-panel-on-command-state = "dsi_lp_mode";
				mi,dsi-panel-nolp-command = [
					//exit AOD ESD detect 0A
					39 00 00 40 00 00 06 F0 55 AA 52 08 00
					15 00 00 40 00 00 02 6F 19
					39 00 00 40 00 00 05 BE 10 0A 00 9C
					05 00 00 40 00 00 01 38
					39 00 00 00 00 00 03 51 00 23
					//1hz
					15 00 00 40 00 00 02 6D 09
					39 00 00 40 00 00 06 F0 55 AA 52 08 00
					15 00 00 40 00 00 02 6F DE
					15 00 00 40 00 00 02 BA 00
					15 00 00 00 00 00 02 8C 00
					//fix TE
					15 00 00 40 00 00 02 6F 14
					15 00 00 40 00 00 02 35 00
					15 00 00 40 00 00 02 6F 04
					15 00 00 40 00 00 02 35 00
					39 00 00 00 00 00 06 F0 55 AA 52 08 0F
				];
				mi,dsi-panel-nolp-command-update = <0x51 4 2>;
				mi,dsi-panel-nolp-command-state = "dsi_hs_mode";
			};
		auto_60_to_10hz_index_08 {
				#include "dsi_panel_o2s_42_02_0a_dsc_cmd_common.dtsi"
				dsi-panel-frame-rate = <60>;
				dsi-panel-te-rate = <120>;
				dsi-panel-base-rate = <120>;
				dsi-panel-vrr-type = <3>;
				/* ---------------------------- */
				/* | 15 - 14 | 13 - 7 | 6 - 0 | */
				/* ---------------------------- */
				/* |   mode  | sf fps | min fps| */
				/* ---------------------------- -*/
				/* mode: 1 idle, 2 auto, 3 qsync */
				/*   2 << 14 | 60 << 7 | 10     */
				dsi-panel-h-sync-skew  = <40458>;
				/* mode: 0 normal, 1 idle, 2 auto, 3 qsync, 4 diff, 5 test */
				mi,dsi-panel-ddic-mode = "auto";
				mi,dsi-panel-sf-framerate = <60>;
				mi,dsi-panel-ddic-min-framerate = <10>;
				dsi-panel-h-front-porch = <12>;
				dsi-panel-h-back-porch = <4>;
				dsi-panel-h-pulse-width = <4>;
				dsi-panel-v-back-porch = <24>;
				dsi-panel-v-front-porch = <64>;
				dsi-panel-v-pulse-width = <4>;
				dsi-panel-timing-switch-command = [
					//10hz
					15 00 00 40 00 00 02 6D 0D
					39 00 00 40 00 00 06 F0 55 AA 52 08 00
					15 00 00 40 00 00 02 6F DE
					15 00 00 40 00 00 02 BA 00
					15 00 00 00 00 00 02 8C 00
					//fix TE
					15 00 00 40 00 00 02 6F 14
					15 00 00 40 00 00 02 35 00
					15 00 00 40 00 00 02 6F 04
					15 00 00 00 00 00 02 35 00
				];
				dsi-panel-timing-switch-command-state = "dsi_hs_mode";
				dsi-panel-on-command = [
					#include "dsi_panel_o2s_42_02_0a_dsc_cmd_on_common.dtsi"
					//timing config
					15 00 00 40 00 00 02 2F 32
 					//10hz
					15 00 00 40 00 00 02 6D 0D
					39 00 00 40 00 00 06 F0 55 AA 52 08 00
					15 00 00 40 00 00 02 6F DE
					15 00 00 40 00 00 02 BA 00
					15 00 00 00 00 00 02 8C 00
					//fix TE
					15 00 00 40 00 00 02 6F 14
					15 00 00 40 00 00 02 35 00
					15 00 00 40 00 00 02 6F 04
					15 00 00 40 00 00 02 35 00
					15 00 00 00 00 00 02 5A 00
					//51 return in fps
					39 00 00 00 00 00 04 8C 00 00 11
					/* Sleep Out */
					05 00 00 00 78 00 01 11
					39 00 00 40 00 00 06 F0 55 AA 52 08 02
					15 00 00 00 00 00 02 CC 10
					39 00 00 40 00 00 06 F0 55 AA 52 08 09
					15 00 00 40 00 00 02 6F 03
					39 00 00 40 00 00 05 B2 20 24 28 2C
					15 00 00 40 00 00 02 B2 02
					15 00 00 40 00 00 02 DD 01
					15 00 00 40 00 00 02 6F 11
					39 00 00 40 00 00 20 B2 00 40 00 00 00 00 00 00 00 00 00 00 00 F0 FA
										FB FD 03 04 05 05 0D 0A 0A 02 02 02 02 00 00 00
					15 00 00 40 00 00 02 6F 11
					39 00 00 40 00 00 20 B2 01 40 00 00 00 00 00 00 00 00 00 0A 0A 07 06
										08 07 07 07 07 07 07 09 08 0A 05 06 05 00 00 00
					15 00 00 40 00 00 02 6F 11
					39 00 00 40 00 00 20 B2 00 41 00 00 00 00 00 00 00 F4 F4 F4 F4 FA FC
										00 02 0A 0C 0C 0A 0A 0A 0A 00 00 00 00 00 00 00
					15 00 00 40 00 00 02 6F 11
					39 00 00 40 00 00 20 B2 01 41 00 00 00 00 00 00 0D 0D 0D 0D 0F 0D 07
										08 07 07 07 07 06 05 05 05 05 04 03 00 00 00 00
					15 00 00 40 00 00 02 6F 11
					39 00 00 40 00 00 20 B2 00 42 00 00 00 00 00 01 01 01 DF FF FF 01 04
										08 0A 0A 12 0C 0A 0A 0A 0A 05 04 03 01 00 00 00
					15 00 00 40 00 00 02 6F 11
					39 00 00 40 00 00 20 B2 01 42 00 00 00 00 00 00 03 03 0A 0A 0A 0A 0B
										0B 0A 09 09 05 05 05 05 03 03 03 00 00 00 00 00
					15 00 00 40 00 00 02 6F 11
					39 00 00 40 00 00 20 B2 00 43 00 00 00 00 00 01 01 CA D7 03 FD 01 05
										0B 0E 06 06 09 0A 0A 08 04 00 00 00 00 00 00 00
					15 00 00 40 00 00 02 6F 11
					39 00 00 40 00 00 20 B2 01 43 00 00 00 00 00 00 03 F8 08 08 08 08 08
										08 0A 0A 04 04 05 05 05 FE 00 00 00 00 00 00 00
					15 00 00 40 00 00 02 6F 11
					39 00 00 40 00 00 20 B2 00 50 00 00 00 00 00 00 00 00 00 00 F3 F3 F3
										F7 F8 00 03 04 0C 0C 0A 0A 0A 06 06 06 00 00 00
					15 00 00 40 00 00 02 6F 11
					39 00 00 40 00 00 20 B2 01 50 00 00 00 00 00 00 00 00 00 0D 0D 0D 0D
										0A 0A 08 08 08 08 08 0A 0F 10 0F 07 08 00 00 00
					15 00 00 40 00 00 02 6F 11
					39 00 00 40 00 00 20 B2 00 51 00 00 00 00 00 00 00 00 00 00 E8 F0 F5
										FA 00 06 09 0A 09 05 09 02 02 00 00 00 00 00 00
					15 00 00 40 00 00 02 6F 11
					39 00 00 40 00 00 20 B2 01 51 00 00 00 00 00 00 00 00 00 00 0F 0F 09
										0B 0A 0A 07 08 08 08 06 04 02 02 02 01 00 00 00
					15 00 00 40 00 00 02 6F 11
					39 00 00 40 00 00 20 B2 00 52 00 00 00 00 00 00 00 00 00 F0 F0 F2 F8
										00 02 02 04 02 06 04 08 02 00 00 00 00 00 00 00
					15 00 00 40 00 00 02 6F 11
					39 00 00 40 00 00 20 B2 01 52 00 00 00 00 00 00 05 0B 0B 0A 0C 09 06
										06 09 0A 09 08 04 06 04 00 00 00 00 00 00 00 00
					15 00 00 40 00 00 02 6F 11
					39 00 00 40 00 00 20 B2 00 53 00 00 00 00 00 00 00 00 00 00 F0 F9 00
										02 02 01 02 02 06 04 08 02 00 00 00 00 00 00 00
					15 00 00 40 00 00 02 6F 11
					39 00 00 40 00 00 20 B2 01 53 00 00 00 00 00 00 05 0B 0B 0A 0C 07 0B
										0A 09 0A 09 08 04 06 04 00 00 00 00 00 00 00 00
					15 00 00 40 00 00 02 6F 11
					39 00 00 40 00 00 20 B2 00 60 00 00 00 00 00 00 00 00 00 00 DD 00 00
										00 00 00 00 00 00 03 08 04 08 06 06 06 00 00 00
					15 00 00 40 00 00 02 6F 11
					39 00 00 40 00 00 20 B2 01 60 00 00 00 00 00 00 00 00 00 00 11 0D 0D
										0A 0A 08 08 08 08 08 09 0A 12 0F 07 08 00 00 00
					15 00 00 40 00 00 02 6F 11
					39 00 00 40 00 00 20 B2 00 61 00 00 00 00 00 00 00 00 BD DD 00 E0 E6
										EC F5 FD 00 06 06 03 08 08 08 06 06 06 00 00 00
					15 00 00 40 00 00 02 6F 11
					39 00 00 40 00 00 20 B2 01 61 00 00 00 00 00 00 00 00 00 00 11 0D 0D
										0A 0A 08 08 08 08 08 0A 0F 10 0F 07 08 00 00 00
					15 00 00 40 00 00 02 6F 11
					39 00 00 40 00 00 20 B2 00 62 00 00 00 00 00 00 00 00 D7 F5 00 DC EC
										F4 03 06 08 08 06 16 0D 0A 0A 06 08 0A 00 00 00
					15 00 00 40 00 00 02 6F 11
					39 00 00 40 00 00 20 B2 01 62 00 00 00 00 00 00 00 00 0C 0C 0E 0D 0A
										09 0A 08 06 06 06 0F 0A 08 03 00 00 00 00 00 00
					15 00 00 40 00 00 02 6F 11
					39 00 00 40 00 00 20 B2 00 63 00 00 00 00 00 00 00 00 00 C7 EF EF FA
										00 0A 0A 0D 14 14 11 0F 0A 0A 06 08 0A 00 00 00
					15 00 00 40 00 00 02 6F 11
					39 00 00 40 00 00 20 B2 01 63 00 00 00 00 00 00 00 00 00 0D 10 0D 0A
										07 08 07 07 06 0A 07 06 05 00 00 00 00 00 00 00
					15 00 00 40 00 00 02 DD 00
					39 00 00 40 00 00 06 F0 55 AA 52 08 02
					15 00 00 00 00 00 02 CC 00
					//vgl lvd 9V
					39 00 00 40 00 00 06 F0 55 AA 52 08 01
					15 00 00 40 00 00 02 6F 03
					39 00 00 00 00 00 03 C7 E7 50
					//force cmd mode
					39 00 00 40 00 00 04 17 30 00 12
					39 00 00 40 00 00 05 FF AA 55 A5 81
					15 00 00 40 00 00 02 6F 0F
					39 00 00 00 00 00 02 FD 80
					//APL Dimming
					39 00 00 40 00 00 06 F0 55 AA 52 08 00
					15 00 00 40 00 00 02 6F 78
					39 00 00 40 00 00 18 B0 11 00 2A 00 C2 01 DA 03 7C 05 B1 08 80 0B EE 0F FF 05 55 05 56 05 55
					15 00 00 40 00 00 02 6F 6F
					39 00 00 40 00 00 07 B0 02 D0 05 A0 02 D0
					39 00 00 40 00 00 06 F0 55 AA 52 08 08
					//Lv0 1260nits
					39 00 00 40 00 00 17 C1 9D FF DD FF FF DD FF FF DD FF FF DD FF FF ED FF FF FF 7F FF 0D FF
					15 00 00 40 00 00 02 6F 1D
					39 00 00 40 00 00 07 C1 00 FF FF 4F 00 FF
					15 00 00 40 00 00 02 6F 23
					39 00 00 40 00 00 15 C1 0D FF DD FF FF DD FF FF DD FF FF DD FF FF ED FF FF BD 2D 00
					//Lv1 1800nits
					15 00 00 40 00 00 02 6F 37
					39 00 00 40 00 00 15 C1 0D FF DD FF FF DD FF FF DD FF FF DD FF FF ED FF FF FF 7F FF
					15 00 00 40 00 00 02 6F 4B
					39 00 00 40 00 00 15 C1 0D FF DD FF FF DD FF FF DD FF FF DD FF FF ED FF FF DF 7F 11
					39 00 00 40 00 00 2D BA 00 0F 00 1D 00 1D 00 31 00 31 00 53 00 53 01 9B 01 9B 01 9C
								01 9C 05 56 05 56 0F FF 0F FF 15 54 15 54 21 98 21 98 2F FD 2F FD 3F FF
					15 00 00 40 00 00 02 6F 07
					15 00 00 00 00 00 02 51 00
					/* Display On */
					05 00 00 00 00 00 01 29
					39 00 00 40 00 00 06 F0 55 AA 52 08 04
					15 00 00 40 00 00 02 6F 06
					39 00 00 00 00 00 04 CB 00 03 12
					39 00 00 40 00 00 06 F0 55 AA 52 08 08
					39 00 00 40 00 00 0F E1 00 00 00 00 00 00 00 00 00 00 00 00 00 00
					39 00 00 40 00 00 0F E2 00 00 00 00 02 05 08 0A 25 25 27 28 28 28
					39 00 00 00 00 00 0F E3 00 00 00 00 00 00 00 00 10 18 1A 1C 1E 20
					39 00 00 00 00 00 06 F0 55 AA 52 08 0F
				];
				dsi-panel-on-command-state = "dsi_lp_mode";
				mi,dsi-panel-nolp-command = [
					//exit AOD ESD detect 0A
					39 00 00 40 00 00 06 F0 55 AA 52 08 00
					15 00 00 40 00 00 02 6F 19
					39 00 00 40 00 00 05 BE 10 0A 00 9C
					05 00 00 40 00 00 01 38
					39 00 00 00 00 00 03 51 00 23
					//10hz
					15 00 00 40 00 00 02 6D 0D
					39 00 00 40 00 00 06 F0 55 AA 52 08 00
					15 00 00 40 00 00 02 6F DE
					15 00 00 40 00 00 02 BA 00
					15 00 00 00 00 00 02 8C 00
					//fix TE
					15 00 00 40 00 00 02 6F 14
					15 00 00 40 00 00 02 35 00
					15 00 00 40 00 00 02 6F 04
					15 00 00 40 00 00 02 35 00
					39 00 00 00 00 00 06 F0 55 AA 52 08 0F
				];
				mi,dsi-panel-nolp-command-update = <0x51 4 2>;
				mi,dsi-panel-nolp-command-state = "dsi_hs_mode";
			};
		auto_120_to_30hz_index_09 {
				#include "dsi_panel_o2s_42_02_0a_dsc_cmd_common.dtsi"
				dsi-panel-frame-rate = <120>;
				dsi-panel-te-rate = <120>;
				dsi-panel-base-rate = <120>;
				dsi-panel-vrr-type = <3>;
				/* ---------------------------- */
				/* | 15 - 14 | 13 - 7 | 6 - 0 | */
				/* ---------------------------- */
				/* |   mode  | sf fps | min fps| */
				/* ---------------------------- -*/
				/* mode: 1 idle, 2 auto, 3 qsync */
				/*   2 << 14 | 120 << 7 | 30     */
				dsi-panel-h-sync-skew  = <48158>;
				/* mode: 0 normal, 1 idle, 2 auto, 3 qsync, 4 diff, 5 test */
				mi,dsi-panel-ddic-mode = "auto";
				mi,dsi-panel-sf-framerate = <120>;
				mi,dsi-panel-ddic-min-framerate = <30>;
				dsi-panel-h-front-porch = <12>;
				dsi-panel-h-back-porch = <4>;
				dsi-panel-h-pulse-width = <4>;
				dsi-panel-v-back-porch = <24>;
				dsi-panel-v-front-porch = <64>;
				dsi-panel-v-pulse-width = <4>;
				dsi-panel-timing-switch-command = [
					//30hz AUTO 120HZ
					15 00 00 40 00 00 02 6D 0C
					39 00 00 40 00 00 06 F0 55 AA 52 08 00
					15 00 00 40 00 00 02 6F DE
					15 00 00 40 00 00 02 BA 00
					15 00 00 00 00 00 02 8C 00
					//fix TE
					15 00 00 40 00 00 02 6F 14
					15 00 00 40 00 00 02 35 00
					15 00 00 40 00 00 02 6F 04
					15 00 00 00 00 00 02 35 00
				];
				dsi-panel-timing-switch-command-state = "dsi_hs_mode";
				dsi-panel-on-command = [
					#include "dsi_panel_o2s_42_02_0a_dsc_cmd_on_common.dtsi"
					//timing config
					15 00 00 40 00 00 02 2F 32
 					//30hz AUTO 120HZ
					15 00 00 40 00 00 02 6D 0C
					39 00 00 40 00 00 06 F0 55 AA 52 08 00
					15 00 00 40 00 00 02 6F DE
					15 00 00 40 00 00 02 BA 00
					15 00 00 00 00 00 02 8C 00
					//fix TE
					15 00 00 40 00 00 02 6F 14
					15 00 00 40 00 00 02 35 00
					15 00 00 40 00 00 02 6F 04
					15 00 00 40 00 00 02 35 00
					15 00 00 00 00 00 02 5A 00
					//51 return in fps
					39 00 00 00 00 00 04 8C 00 00 11
					/* Sleep Out */
					05 00 00 00 78 00 01 11
					39 00 00 40 00 00 06 F0 55 AA 52 08 02
					15 00 00 00 00 00 02 CC 10
					39 00 00 40 00 00 06 F0 55 AA 52 08 09
					15 00 00 40 00 00 02 6F 03
					39 00 00 40 00 00 05 B2 20 24 28 2C
					15 00 00 40 00 00 02 B2 02
					15 00 00 40 00 00 02 DD 01
					15 00 00 40 00 00 02 6F 11
					39 00 00 40 00 00 20 B2 00 40 00 00 00 00 00 00 00 00 00 00 00 F0 FA
										FB FD 03 04 05 05 0D 0A 0A 02 02 02 02 00 00 00
					15 00 00 40 00 00 02 6F 11
					39 00 00 40 00 00 20 B2 01 40 00 00 00 00 00 00 00 00 00 0A 0A 07 06
										08 07 07 07 07 07 07 09 08 0A 05 06 05 00 00 00
					15 00 00 40 00 00 02 6F 11
					39 00 00 40 00 00 20 B2 00 41 00 00 00 00 00 00 00 F4 F4 F4 F4 FA FC
										00 02 0A 0C 0C 0A 0A 0A 0A 00 00 00 00 00 00 00
					15 00 00 40 00 00 02 6F 11
					39 00 00 40 00 00 20 B2 01 41 00 00 00 00 00 00 0D 0D 0D 0D 0F 0D 07
										08 07 07 07 07 06 05 05 05 05 04 03 00 00 00 00
					15 00 00 40 00 00 02 6F 11
					39 00 00 40 00 00 20 B2 00 42 00 00 00 00 00 01 01 01 DF FF FF 01 04
										08 0A 0A 12 0C 0A 0A 0A 0A 05 04 03 01 00 00 00
					15 00 00 40 00 00 02 6F 11
					39 00 00 40 00 00 20 B2 01 42 00 00 00 00 00 00 03 03 0A 0A 0A 0A 0B
										0B 0A 09 09 05 05 05 05 03 03 03 00 00 00 00 00
					15 00 00 40 00 00 02 6F 11
					39 00 00 40 00 00 20 B2 00 43 00 00 00 00 00 01 01 CA D7 03 FD 01 05
										0B 0E 06 06 09 0A 0A 08 04 00 00 00 00 00 00 00
					15 00 00 40 00 00 02 6F 11
					39 00 00 40 00 00 20 B2 01 43 00 00 00 00 00 00 03 F8 08 08 08 08 08
										08 0A 0A 04 04 05 05 05 FE 00 00 00 00 00 00 00
					15 00 00 40 00 00 02 6F 11
					39 00 00 40 00 00 20 B2 00 50 00 00 00 00 00 00 00 00 00 00 F3 F3 F3
										F7 F8 00 03 04 0C 0C 0A 0A 0A 06 06 06 00 00 00
					15 00 00 40 00 00 02 6F 11
					39 00 00 40 00 00 20 B2 01 50 00 00 00 00 00 00 00 00 00 0D 0D 0D 0D
										0A 0A 08 08 08 08 08 0A 0F 10 0F 07 08 00 00 00
					15 00 00 40 00 00 02 6F 11
					39 00 00 40 00 00 20 B2 00 51 00 00 00 00 00 00 00 00 00 00 E8 F0 F5
										FA 00 06 09 0A 09 05 09 02 02 00 00 00 00 00 00
					15 00 00 40 00 00 02 6F 11
					39 00 00 40 00 00 20 B2 01 51 00 00 00 00 00 00 00 00 00 00 0F 0F 09
										0B 0A 0A 07 08 08 08 06 04 02 02 02 01 00 00 00
					15 00 00 40 00 00 02 6F 11
					39 00 00 40 00 00 20 B2 00 52 00 00 00 00 00 00 00 00 00 F0 F0 F2 F8
										00 02 02 04 02 06 04 08 02 00 00 00 00 00 00 00
					15 00 00 40 00 00 02 6F 11
					39 00 00 40 00 00 20 B2 01 52 00 00 00 00 00 00 05 0B 0B 0A 0C 09 06
										06 09 0A 09 08 04 06 04 00 00 00 00 00 00 00 00
					15 00 00 40 00 00 02 6F 11
					39 00 00 40 00 00 20 B2 00 53 00 00 00 00 00 00 00 00 00 00 F0 F9 00
										02 02 01 02 02 06 04 08 02 00 00 00 00 00 00 00
					15 00 00 40 00 00 02 6F 11
					39 00 00 40 00 00 20 B2 01 53 00 00 00 00 00 00 05 0B 0B 0A 0C 07 0B
										0A 09 0A 09 08 04 06 04 00 00 00 00 00 00 00 00
					15 00 00 40 00 00 02 6F 11
					39 00 00 40 00 00 20 B2 00 60 00 00 00 00 00 00 00 00 00 00 DD 00 00
										00 00 00 00 00 00 03 08 04 08 06 06 06 00 00 00
					15 00 00 40 00 00 02 6F 11
					39 00 00 40 00 00 20 B2 01 60 00 00 00 00 00 00 00 00 00 00 11 0D 0D
										0A 0A 08 08 08 08 08 09 0A 12 0F 07 08 00 00 00
					15 00 00 40 00 00 02 6F 11
					39 00 00 40 00 00 20 B2 00 61 00 00 00 00 00 00 00 00 BD DD 00 E0 E6
										EC F5 FD 00 06 06 03 08 08 08 06 06 06 00 00 00
					15 00 00 40 00 00 02 6F 11
					39 00 00 40 00 00 20 B2 01 61 00 00 00 00 00 00 00 00 00 00 11 0D 0D
										0A 0A 08 08 08 08 08 0A 0F 10 0F 07 08 00 00 00
					15 00 00 40 00 00 02 6F 11
					39 00 00 40 00 00 20 B2 00 62 00 00 00 00 00 00 00 00 D7 F5 00 DC EC
										F4 03 06 08 08 06 16 0D 0A 0A 06 08 0A 00 00 00
					15 00 00 40 00 00 02 6F 11
					39 00 00 40 00 00 20 B2 01 62 00 00 00 00 00 00 00 00 0C 0C 0E 0D 0A
										09 0A 08 06 06 06 0F 0A 08 03 00 00 00 00 00 00
					15 00 00 40 00 00 02 6F 11
					39 00 00 40 00 00 20 B2 00 63 00 00 00 00 00 00 00 00 00 C7 EF EF FA
										00 0A 0A 0D 14 14 11 0F 0A 0A 06 08 0A 00 00 00
					15 00 00 40 00 00 02 6F 11
					39 00 00 40 00 00 20 B2 01 63 00 00 00 00 00 00 00 00 00 0D 10 0D 0A
										07 08 07 07 06 0A 07 06 05 00 00 00 00 00 00 00
					15 00 00 40 00 00 02 DD 00
					39 00 00 40 00 00 06 F0 55 AA 52 08 02
					15 00 00 00 00 00 02 CC 00
					//vgl lvd 9V
					39 00 00 40 00 00 06 F0 55 AA 52 08 01
					15 00 00 40 00 00 02 6F 03
					39 00 00 00 00 00 03 C7 E7 50
					//force cmd mode
					39 00 00 40 00 00 04 17 30 00 12
					39 00 00 40 00 00 05 FF AA 55 A5 81
					15 00 00 40 00 00 02 6F 0F
					39 00 00 00 00 00 02 FD 80
					//APL Dimming
					39 00 00 40 00 00 06 F0 55 AA 52 08 00
					15 00 00 40 00 00 02 6F 78
					39 00 00 40 00 00 18 B0 11 00 2A 00 C2 01 DA 03 7C 05 B1 08 80 0B EE 0F FF 05 55 05 56 05 55
					15 00 00 40 00 00 02 6F 6F
					39 00 00 40 00 00 07 B0 02 D0 05 A0 02 D0
					39 00 00 40 00 00 06 F0 55 AA 52 08 08
					//Lv0 1260nits
					39 00 00 40 00 00 17 C1 9D FF DD FF FF DD FF FF DD FF FF DD FF FF ED FF FF FF 7F FF 0D FF
					15 00 00 40 00 00 02 6F 1D
					39 00 00 40 00 00 07 C1 00 FF FF 4F 00 FF
					15 00 00 40 00 00 02 6F 23
					39 00 00 40 00 00 15 C1 0D FF DD FF FF DD FF FF DD FF FF DD FF FF ED FF FF BD 2D 00
					//Lv1 1800nits
					15 00 00 40 00 00 02 6F 37
					39 00 00 40 00 00 15 C1 0D FF DD FF FF DD FF FF DD FF FF DD FF FF ED FF FF FF 7F FF
					15 00 00 40 00 00 02 6F 4B
					39 00 00 40 00 00 15 C1 0D FF DD FF FF DD FF FF DD FF FF DD FF FF ED FF FF DF 7F 11
					39 00 00 40 00 00 2D BA 00 0F 00 1D 00 1D 00 31 00 31 00 53 00 53 01 9B 01 9B 01 9C
								01 9C 05 56 05 56 0F FF 0F FF 15 54 15 54 21 98 21 98 2F FD 2F FD 3F FF
					15 00 00 40 00 00 02 6F 07
					15 00 00 00 00 00 02 51 00
					/* Display On */
					05 00 00 00 00 00 01 29
					39 00 00 40 00 00 06 F0 55 AA 52 08 04
					15 00 00 40 00 00 02 6F 06
					39 00 00 00 00 00 04 CB 00 03 12
					39 00 00 40 00 00 06 F0 55 AA 52 08 08
					39 00 00 40 00 00 0F E1 00 00 00 00 00 00 00 00 00 00 00 00 00 00
					39 00 00 40 00 00 0F E2 00 00 00 00 02 05 08 0A 25 25 27 28 28 28
					39 00 00 00 00 00 0F E3 00 00 00 00 00 00 00 00 10 18 1A 1C 1E 20
					39 00 00 00 00 00 06 F0 55 AA 52 08 0F
				];
				dsi-panel-on-command-state = "dsi_lp_mode";
				mi,dsi-panel-nolp-command = [
					//exit AOD ESD detect 0A
					39 00 00 40 00 00 06 F0 55 AA 52 08 00
					15 00 00 40 00 00 02 6F 19
					39 00 00 40 00 00 05 BE 10 0A 00 9C
					05 00 00 40 00 00 01 38
					39 00 00 00 00 00 03 51 00 23
					//30hz AUTO 120HZ
					15 00 00 40 00 00 02 6D 0C
					39 00 00 40 00 00 06 F0 55 AA 52 08 00
					15 00 00 40 00 00 02 6F DE
					15 00 00 40 00 00 02 BA 00
					15 00 00 00 00 00 02 8C 00
					//fix TE
					15 00 00 40 00 00 02 6F 14
					15 00 00 40 00 00 02 35 00
					15 00 00 40 00 00 02 6F 04
					15 00 00 40 00 00 02 35 00
					39 00 00 00 00 00 06 F0 55 AA 52 08 0F
				];
				mi,dsi-panel-nolp-command-update = <0x51 4 2>;
				mi,dsi-panel-nolp-command-state = "dsi_hs_mode";
			};
		};
	};
};

&dsi_panel_o2s_42_02_0a_dsc_cmd {
	mi,panel-id = <0x004F3253 0x0042020A>;
	dsi-panel-esd-check-enable;
	dsi-panel-esd-mode = "err_int";
	dsi-panel-esd-err-irq-gpio-0 = <&dw_gpio0 11 0x2004>; // 11
	dsi-panel-erd-err-irq-gpio-0-flag = <0x2004>;
	dsi-panel-te-gpio = <&dw_gpio4 28 0>;  // 141
	//mi,disable-ic-dimming-flag;
	//mi,panel-on-dimming-delay = <120>;
	mi,panel-ic-dimming-dbv-threshold = <411>;
	mi,panel-reset-post-off-delay = <1>;
	mi,doze-hbm-dbv-level = <412>;
	mi,doze-lbm-dbv-level = <35>;
	mi,dsi-panel-fac-brightness-max-level = <5460>;
	mi,max-brightness-normal = <5460>;
	mi,ddic-round-corner-enabled;
	//mi,panel-demura-change-dbv-threshold = <412>;

	mi,dsi-panel-wp-read-command = [06 01 00 01 00 00 01 A3];
	mi,dsi-panel-wp-read-command-state = "dsi_hs_mode";
	mi,dsi-panel-wp-read-pre-tx-command = [39 00 00 00 00 00 02 6F 7A];
	mi,dsi-panel-wp-read-pre-tx-command-state = "dsi_hs_mode";
	mi,dsi-panel-wp-read-length = <8>;

	mi,dsi-panel-cell-id-read-command = [06 01 00 01 00 00 01 EB];
	mi,dsi-panel-cell-id-read-pre-tx-command = [
		39 00 00 40 00 00 06 F0 55 AA 52 08 00
		39 00 00 00 00 00 02 EA 10
	];
	mi,dsi-panel-cell-id-read-pre-tx-command-state = "dsi_hs_mode";
	mi,dsi-panel-cell-id-read-command-state = "dsi_hs_mode";
	mi,dsi-panel-cell-id-read-length = <13>;

	mi,panel-build-id-read-needed;
	mi,panel-build-id-read-length = <1>;
	mi,dsi-panel-build-id-read-command = [06 01 00 01 00 00 01 DA];
	mi,dsi-panel-build-id-read-command-state = "dsi_hs_mode";

	mi,panel-flatmode-status-check-enabled;
	mi,dsi-panel-flatmode-status-command = [06 01 00 01 00 00 01 5F];
	mi,dsi-panel-flatmode-status-command-state = "dsi_hs_mode";
	mi,dsi-panel-flatmode-status-read-length = <1>;
	mi,dsi-panel-flatmode-on-status-value = <0x00>;
	mi,fps-change-notify-enabled;
	mi,hwc-set-doze-brightness;
};
